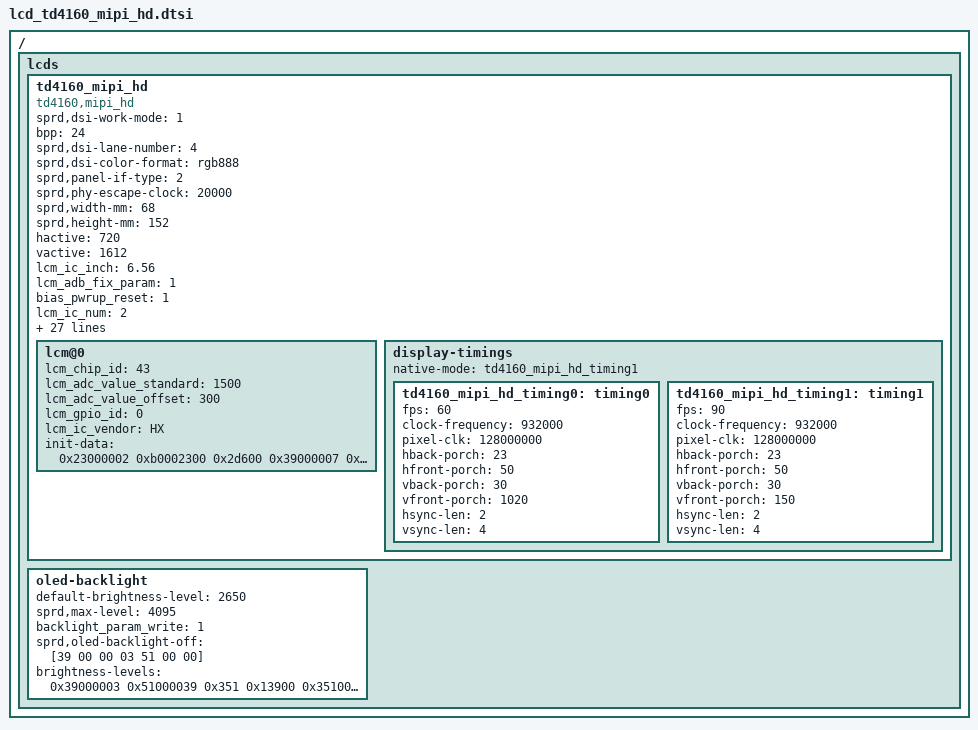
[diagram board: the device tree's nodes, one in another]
/ {
	fragment {
		target-path = "/";
		__overlay__ {
			lcds {
				td4160_mipi_hd: td4160_mipi_hd {
					compatible = "td4160,mipi_hd";
					sprd,dsi-work-mode = <1>; /* video burst mode*/
					bpp = <24>;
					sprd,dsi-lane-number = <4>;
					sprd,dsi-color-format = "rgb888";
					sprd,panel-if-type = <2>;
					sprd,phy-escape-clock = <20000>;
					sprd,width-mm = <68>;
					sprd,height-mm = <152>;
					hactive = <720>;
					vactive = <1612>;
					lcm_ic_inch = "6.56";
					lcm_adb_fix_param = <1>;
					bias_pwrup_reset = <1>;
					lcm_ic_num = <2>;
					lcm_compatible_mode = <1>;
					lcm_adc_channel = <2>;
					tp_touchscreen_rst = <145>;
					tp_touchscreen_irq = <144>;
					tp_touchscreen_cs = <94>;

					sprd,dynamic-framerate-mode;
					sprd,esd-check-enable = <1>;
					sprd,esd-check-mode = <1>;
					sprd,esd-check-period = <2000>;
					sprd,esd-check-register = <10>;
					sprd,esd-check-value = <156>;
					lcm_ic_name = "TD4160";
					lcm_moden_num = <1>;
					lcm_chipid_register = <59>;
					sprd,lcd-id-tokernel = <0x41601>;
					lcm_is_init = <1>;
					power-on-sequence-uboot = <50 1 5 50 0 10 50 1 50>;
					power-on-sequence-kernel = <50 1 5 50 0 10 50 1 50>;
					power-off-sequence = <50 0 1>;
					sprd,oled-backlight-close = [39 00 00 03 51 00 00 23 78 00 02 53 00 13 14 00 01 28];
					sprd,cabc-open = [23 00 00 02 55 01];
					sprd,cabc-close = [23 00 00 02 55 00];
					sleep-in = [13 14 00 01 28 13 78 00 01 10];
					sleep-out = [13 78 00 01 11 13 14 00 01 29];

					lcm@0 {
						lcm_chip_id = <43>;
						lcm_adc_value_standard = <1500>;
						lcm_adc_value_offset = <300>;
						lcm_gpio_id = <0>;
						lcm_ic_vendor = "HX";
						init-data = <0x23000002 0xb0002300 0x2d600 0x39000007 0xb6306a00 0x86c30339 0x5b7 0x31000000 0x39000007 0xb8007864 0x1064b439 0x7b9 0x786410 0x64b43900 0x7ba00 0x78641064 0xb4390000 0x4bb00b4 0xa0390000 0x4bc00b4 0xa0390000 0x4bd00b4 0xa0390000 0xebe070d 0x00 0x00 0x39 0x19c0 0x602206 0x4c001806 0x94007000 0x00 0x00 0x00 0x39000028 0xc1301150 0xfa010000 0x10000000 0x400f00 0x00 0x00 0x00 0x00 0x00 0x00 0x390000f5 0xc203f04c 0x12051008 0x00 0x1010110 0xa000000 0x00 0x00 0x00 0x00 0x00 0x04 0xb03b0c0c 0x5004100 0x46690300 0x64000000 0x1100 0x00 0x00 0x04 0x90360a0a 0x5000166 0xa6730000 0x00 0x1100 0x00 0x00 0x00 0x00 0x00 0x00 0x00 0x1100 0x00 0x00 0x00 0x00 0x00 0x00 0x00 0x1100 0x00 0x00 0x00 0x00 0x00 0x00 0x00 0x00 0x00 0x1000 0x00 0x00 0x00 0x200 0x00 0x00 0x20000 0x00 0x00 0x00 0x00 0x390000 0x6ac30000 0x5dc300c0 0xc3c0c0c 0x20000000 0x00 0x00 0x20000000 0x00 0x00 0x20000000 0x00 0x00 0x20000000 0x80000 0x00 0x00 0x00 0x00 0x00 0x00 0x00 0x00 0x00 0x00 0x00 0x00 0x39 0x55c4 0x707 0x2b272923 0x255d6113 0x1517191b 0x1d030000 0x00 0x00 0x41e1c1a 0x18161461 0x5d26242a 0x282c0707 0x00 0x00 0x00 0x00 0x00 0x00 0x00 0x555555 0x55555555 0x55555555 0x39000006 0xc5080000 0x3900 0x4dc600 0x01 0x22042201 0x5d0000 0x1005d 0x10501 0xb0135ff 0x8f061501 0xc00b0000 0x00 0x00 0x00 0x00 0x00 0x20200000 0xc01100 0x1010 0x01 0x500033 0x3000039 0x1fcb 0x2d00180 0x00 0x00 0x00 0x00 0x4070 0x00 0xff3900 0x19ce5d 0x40434955 0x62718294 0xa8b9cbdb 0xe9f5fcff 0x4000202 0x48c23 0x2cf 0x390000 0x15d0c14a 0x81660990 0xccf2ff 0x1146067e 0x908cc1b 0xf0063900 0x26d1d4 0xd41b3333 0x1707bb33 0x33333300 0x3b77073b 0x30067233 0x1300d70c 0x33020018 0x70187711 0x11112020 0x39000004 0xd2110000 0x3900009a 0xd3000000 0x00 0xfff7 0xfffff7ff 0xfff7ffff 0xf7fffff7 0xfffff7ff 0xfff7ffff 0xf7fffff7 0xfffff7ff 0xfff7ffff 0xf7fffff7 0xfffff7ff 0xfff7ffff 0xf7fffff7 0xfffff7ff 0xfff7ffff 0xf7fffff7 0xfffff7ff 0xfff7ffff 0xf7fffff7 0xfffff7ff 0xfff7ffff 0xf7fffff7 0xfffff7ff 0xfff7ffff 0xf7fffff7 0xfffff7ff 0xfff7ffff 0xf7fffff7 0xfffff7ff 0xfff7ffff 0xf7fffff7 0xfffff7ff 0xfff7ffff 0xf7fffff7 0xfffff7ff 0xfff7ffff 0xf7ff3900 0x18d400 0x00 0x00 0x20000000 0x200000 0x00 0x3900 0x2fd729 0x121200 0x60001800 0x60001803 0x83808585 0x85878445 0x86878088 0x86898383 0x8784888a 0xc0b0a0a 0xa070706 0x600080a 0xa390000 0x17d84099 0x26ed166c 0x166c166c 0x140014 0x14010c 0x100 0x39000029 0xd9000259 0x11b00 0x00 0x00 0xc0000000 0x00 0x00 0x00 0x00 0x00 0x390000 0x5dd3006 0x23653900 0xfde00 0xfff 0x00 0x10000000 0x390000 0x9e60000 0x00 0x3900 0x24ea02 0xe0e0680 0x7407400 0x333 0x70a005e 0x5e005e 0x1280128 0x5e005e 0x5e000c 0x2003900 0x9eb07 0x40740e11 0x1080039 0x18ec 0x5f00170 0x6b074074 0x02 0x2a000000 0x00 0x39 0x22ed 0x1020000 0x100 0x6886fc00 0x00 0x00 0x2b0 0x00 0xc010 0x390000 0x7aee0500 0x5500c05f 0xc05f00 0x30000 0x300c05f 0x00 0xc05f00 0x00 0x30000 0x00 0x3000000 0x03 0xc05f00 0x00 0x30000 0x00 0x3000000 0x03 0x00 0x300 0x30000 0x3000003 0x300 0x30000 0x3000000 0x00 0x00 0x00 0x00 0x00 0x239 0x4f0 0xc1018123 0x235 0x230000 0x2b00339 0x351 0x2300 0x2532c 0x23000002 0x55031350 0x11113 0xa000129>;
					};

					display-timings {
						native-mode = <&td4160_mipi_hd_timing1>;

						td4160_mipi_hd_timing0: timing0 {
							fps = <60>;
							clock-frequency = <932000>;
							pixel-clk = <128000000>;
							hback-porch = <23>;
							hfront-porch = <50>;
							vback-porch = <30>;
							vfront-porch = <1020>;
							hsync-len = <2>;
							vsync-len = <4>;
						};

						td4160_mipi_hd_timing1: timing1 {
							fps = <90>;
							clock-frequency = <932000>;
							pixel-clk = <128000000>;
							hback-porch = <23>;
							hfront-porch = <50>;
							vback-porch = <30>;
							vfront-porch = <150>;
							hsync-len = <2>;
							vsync-len = <4>;
						};
					};
				};

				oled-backlight {
					default-brightness-level = <2650>;
					sprd,max-level = <4095>;
					backlight_param_write = <1>;
					sprd,oled-backlight-off = [39 00 00 03 51 00 00];
					brightness-levels = <0x39000003 0x51000039 0x351 0x13900 0x35100 0x2390000 0x3510003 0x39000003 0x51000439 0x351 0x53900 0x35100 0x6390000 0x3510007 0x39000003 0x51000839 0x351 0x93900 0x35100 0xa390000 0x351000b 0x39000003 0x51000c39 0x351 0xd3900 0x35100 0xe390000 0x351000f 0x39000003 0x51001039 0x351 0x113900 0x35100 0x12390000 0x3510013 0x39000003 0x51001439 0x351 0x153900 0x35100 0x16390000 0x3510017 0x39000003 0x51001839 0x351 0x193900 0x35100 0x1a390000 0x351001b 0x39000003 0x51001c39 0x351 0x1d3900 0x35100 0x1e390000 0x351001f 0x39000003 0x51002039 0x351 0x213900 0x35100 0x22390000 0x3510023 0x39000003 0x51002439 0x351 0x253900 0x35100 0x26390000 0x3510027 0x39000003 0x51002839 0x351 0x293900 0x35100 0x2a390000 0x351002b 0x39000003 0x51002c39 0x351 0x2d3900 0x35100 0x2e390000 0x351002f 0x39000003 0x51003039 0x351 0x313900 0x35100 0x32390000 0x3510033 0x39000003 0x51003439 0x351 0x353900 0x35100 0x36390000 0x3510037 0x39000003 0x51003839 0x351 0x393900 0x35100 0x3a390000 0x351003b 0x39000003 0x51003c39 0x351 0x3d3900 0x35100 0x3e390000 0x351003f 0x39000003 0x51004039 0x351 0x413900 0x35100 0x42390000 0x3510043 0x39000003 0x51004439 0x351 0x453900 0x35100 0x46390000 0x3510047 0x39000003 0x51004839 0x351 0x493900 0x35100 0x4a390000 0x351004b 0x39000003 0x51004c39 0x351 0x4d3900 0x35100 0x4e390000 0x351004f 0x39000003 0x51005039 0x351 0x513900 0x35100 0x52390000 0x3510053 0x39000003 0x51005439 0x351 0x553900 0x35100 0x56390000 0x3510057 0x39000003 0x51005839 0x351 0x593900 0x35100 0x5a390000 0x351005b 0x39000003 0x51005c39 0x351 0x5d3900 0x35100 0x5e390000 0x351005f 0x39000003 0x51006039 0x351 0x613900 0x35100 0x62390000 0x3510063 0x39000003 0x51006439 0x351 0x653900 0x35100 0x66390000 0x3510067 0x39000003 0x51006839 0x351 0x693900 0x35100 0x6a390000 0x351006b 0x39000003 0x51006c39 0x351 0x6d3900 0x35100 0x6e390000 0x351006f 0x39000003 0x51007039 0x351 0x713900 0x35100 0x72390000 0x3510073 0x39000003 0x51007439 0x351 0x753900 0x35100 0x76390000 0x3510077 0x39000003 0x51007839 0x351 0x793900 0x35100 0x7a390000 0x351007b 0x39000003 0x51007c39 0x351 0x7d3900 0x35100 0x7e390000 0x351007f 0x39000003 0x51008039 0x351 0x813900 0x35100 0x82390000 0x3510083 0x39000003 0x51008439 0x351 0x853900 0x35100 0x86390000 0x3510087 0x39000003 0x51008839 0x351 0x893900 0x35100 0x8a390000 0x351008b 0x39000003 0x51008c39 0x351 0x8d3900 0x35100 0x8e390000 0x351008f 0x39000003 0x51009039 0x351 0x913900 0x35100 0x92390000 0x3510093 0x39000003 0x51009439 0x351 0x953900 0x35100 0x96390000 0x3510097 0x39000003 0x51009839 0x351 0x993900 0x35100 0x9a390000 0x351009b 0x39000003 0x51009c39 0x351 0x9d3900 0x35100 0x9e390000 0x351009f 0x39000003 0x5100a039 0x351 0xa13900 0x35100 0xa2390000 0x35100a3 0x39000003 0x5100a439 0x351 0xa53900 0x35100 0xa6390000 0x35100a7 0x39000003 0x5100a839 0x351 0xa93900 0x35100 0xaa390000 0x35100ab 0x39000003 0x5100ac39 0x351 0xad3900 0x35100 0xae390000 0x35100af 0x39000003 0x5100b039 0x351 0xb13900 0x35100 0xb2390000 0x35100b3 0x39000003 0x5100b439 0x351 0xb53900 0x35100 0xb6390000 0x35100b7 0x39000003 0x5100b839 0x351 0xb93900 0x35100 0xba390000 0x35100bb 0x39000003 0x5100bc39 0x351 0xbd3900 0x35100 0xbe390000 0x35100bf 0x39000003 0x5100c039 0x351 0xc13900 0x35100 0xc2390000 0x35100c3 0x39000003 0x5100c439 0x351 0xc53900 0x35100 0xc6390000 0x35100c7 0x39000003 0x5100c839 0x351 0xc93900 0x35100 0xca390000 0x35100cb 0x39000003 0x5100cc39 0x351 0xcd3900 0x35100 0xce390000 0x35100cf 0x39000003 0x5100d039 0x351 0xd13900 0x35100 0xd2390000 0x35100d3 0x39000003 0x5100d439 0x351 0xd53900 0x35100 0xd6390000 0x35100d7 0x39000003 0x5100d839 0x351 0xd93900 0x35100 0xda390000 0x35100db 0x39000003 0x5100dc39 0x351 0xdd3900 0x35100 0xde390000 0x35100df 0x39000003 0x5100e039 0x351 0xe13900 0x35100 0xe2390000 0x35100e3 0x39000003 0x5100e439 0x351 0xe53900 0x35100 0xe6390000 0x35100e7 0x39000003 0x5100e839 0x351 0xe93900 0x35100 0xea390000 0x35100eb 0x39000003 0x5100ec39 0x351 0xed3900 0x35100 0xee390000 0x35100ef 0x39000003 0x5100f039 0x351 0xf13900 0x35100 0xf2390000 0x35100f3 0x39000003 0x5100f439 0x351 0xf53900 0x35100 0xf6390000 0x35100f7 0x39000003 0x5100f839 0x351 0xf93900 0x35100 0xfa390000 0x35100fb 0x39000003 0x5100fc39 0x351 0xfd3900 0x35100 0xfe390000 0x35100ff 0x39000003 0x51010039 0x351 0x1013900 0x35101 0x2390000 0x3510103 0x39000003 0x51010439 0x351 0x1053900 0x35101 0x6390000 0x3510107 0x39000003 0x51010839 0x351 0x1093900 0x35101 0xa390000 0x351010b 0x39000003 0x51010c39 0x351 0x10d3900 0x35101 0xe390000 0x351010f 0x39000003 0x51011039 0x351 0x1113900 0x35101 0x12390000 0x3510113 0x39000003 0x51011439 0x351 0x1153900 0x35101 0x16390000 0x3510117 0x39000003 0x51011839 0x351 0x1193900 0x35101 0x1a390000 0x351011b 0x39000003 0x51011c39 0x351 0x11d3900 0x35101 0x1e390000 0x351011f 0x39000003 0x51012039 0x351 0x1213900 0x35101 0x22390000 0x3510123 0x39000003 0x51012439 0x351 0x1253900 0x35101 0x26390000 0x3510127 0x39000003 0x51012839 0x351 0x1293900 0x35101 0x2a390000 0x351012b 0x39000003 0x51012c39 0x351 0x12d3900 0x35101 0x2e390000 0x351012f 0x39000003 0x51013039 0x351 0x1313900 0x35101 0x32390000 0x3510133 0x39000003 0x51013439 0x351 0x1353900 0x35101 0x36390000 0x3510137 0x39000003 0x51013839 0x351 0x1393900 0x35101 0x3a390000 0x351013b 0x39000003 0x51013c39 0x351 0x13d3900 0x35101 0x3e390000 0x351013f 0x39000003 0x51014039 0x351 0x1413900 0x35101 0x42390000 0x3510143 0x39000003 0x51014439 0x351 0x1453900 0x35101 0x46390000 0x3510147 0x39000003 0x51014839 0x351 0x1493900 0x35101 0x4a390000 0x351014b 0x39000003 0x51014c39 0x351 0x14d3900 0x35101 0x4e390000 0x351014f 0x39000003 0x51015039 0x351 0x1513900 0x35101 0x52390000 0x3510153 0x39000003 0x51015439 0x351 0x1553900 0x35101 0x56390000 0x3510157 0x39000003 0x51015839 0x351 0x1593900 0x35101 0x5a390000 0x351015b 0x39000003 0x51015c39 0x351 0x15d3900 0x35101 0x5e390000 0x351015f 0x39000003 0x51016039 0x351 0x1613900 0x35101 0x62390000 0x3510163 0x39000003 0x51016439 0x351 0x1653900 0x35101 0x66390000 0x3510167 0x39000003 0x51016839 0x351 0x1693900 0x35101 0x6a390000 0x351016b 0x39000003 0x51016c39 0x351 0x16d3900 0x35101 0x6e390000 0x351016f 0x39000003 0x51017039 0x351 0x1713900 0x35101 0x72390000 0x3510173 0x39000003 0x51017439 0x351 0x1753900 0x35101 0x76390000 0x3510177 0x39000003 0x51017839 0x351 0x1793900 0x35101 0x7a390000 0x351017b 0x39000003 0x51017c39 0x351 0x17d3900 0x35101 0x7e390000 0x351017f 0x39000003 0x51018039 0x351 0x1813900 0x35101 0x82390000 0x3510183 0x39000003 0x51018439 0x351 0x1853900 0x35101 0x86390000 0x3510187 0x39000003 0x51018839 0x351 0x1893900 0x35101 0x8a390000 0x351018b 0x39000003 0x51018c39 0x351 0x18d3900 0x35101 0x8e390000 0x351018f 0x39000003 0x51019039 0x351 0x1913900 0x35101 0x92390000 0x3510193 0x39000003 0x51019439 0x351 0x1953900 0x35101 0x96390000 0x3510197 0x39000003 0x51019839 0x351 0x1993900 0x35101 0x9a390000 0x351019b 0x39000003 0x51019c39 0x351 0x19d3900 0x35101 0x9e390000 0x351019f 0x39000003 0x5101a039 0x351 0x1a13900 0x35101 0xa2390000 0x35101a3 0x39000003 0x5101a439 0x351 0x1a53900 0x35101 0xa6390000 0x35101a7 0x39000003 0x5101a839 0x351 0x1a93900 0x35101 0xaa390000 0x35101ab 0x39000003 0x5101ac39 0x351 0x1ad3900 0x35101 0xae390000 0x35101af 0x39000003 0x5101b039 0x351 0x1b13900 0x35101 0xb2390000 0x35101b3 0x39000003 0x5101b439 0x351 0x1b53900 0x35101 0xb6390000 0x35101b7 0x39000003 0x5101b839 0x351 0x1b93900 0x35101 0xba390000 0x35101bb 0x39000003 0x5101bc39 0x351 0x1bd3900 0x35101 0xbe390000 0x35101bf 0x39000003 0x5101c039 0x351 0x1c13900 0x35101 0xc2390000 0x35101c3 0x39000003 0x5101c439 0x351 0x1c53900 0x35101 0xc6390000 0x35101c7 0x39000003 0x5101c839 0x351 0x1c93900 0x35101 0xca390000 0x35101cb 0x39000003 0x5101cc39 0x351 0x1cd3900 0x35101 0xce390000 0x35101cf 0x39000003 0x5101d039 0x351 0x1d13900 0x35101 0xd2390000 0x35101d3 0x39000003 0x5101d439 0x351 0x1d53900 0x35101 0xd6390000 0x35101d7 0x39000003 0x5101d839 0x351 0x1d93900 0x35101 0xda390000 0x35101db 0x39000003 0x5101dc39 0x351 0x1dd3900 0x35101 0xde390000 0x35101df 0x39000003 0x5101e039 0x351 0x1e13900 0x35101 0xe2390000 0x35101e3 0x39000003 0x5101e439 0x351 0x1e53900 0x35101 0xe6390000 0x35101e7 0x39000003 0x5101e839 0x351 0x1e93900 0x35101 0xea390000 0x35101eb 0x39000003 0x5101ec39 0x351 0x1ed3900 0x35101 0xee390000 0x35101ef 0x39000003 0x5101f039 0x351 0x1f13900 0x35101 0xf2390000 0x35101f3 0x39000003 0x5101f439 0x351 0x1f53900 0x35101 0xf6390000 0x35101f7 0x39000003 0x5101f839 0x351 0x1f93900 0x35101 0xfa390000 0x35101fb 0x39000003 0x5101fc39 0x351 0x1fd3900 0x35101 0xfe390000 0x35101ff 0x39000003 0x51020039 0x351 0x2013900 0x35102 0x2390000 0x3510203 0x39000003 0x51020439 0x351 0x2053900 0x35102 0x6390000 0x3510207 0x39000003 0x51020839 0x351 0x2093900 0x35102 0xa390000 0x351020b 0x39000003 0x51020c39 0x351 0x20d3900 0x35102 0xe390000 0x351020f 0x39000003 0x51021039 0x351 0x2113900 0x35102 0x12390000 0x3510213 0x39000003 0x51021439 0x351 0x2153900 0x35102 0x16390000 0x3510217 0x39000003 0x51021839 0x351 0x2193900 0x35102 0x1a390000 0x351021b 0x39000003 0x51021c39 0x351 0x21d3900 0x35102 0x1e390000 0x351021f 0x39000003 0x51022039 0x351 0x2213900 0x35102 0x22390000 0x3510223 0x39000003 0x51022439 0x351 0x2253900 0x35102 0x26390000 0x3510227 0x39000003 0x51022839 0x351 0x2293900 0x35102 0x2a390000 0x351022b 0x39000003 0x51022c39 0x351 0x22d3900 0x35102 0x2e390000 0x351022f 0x39000003 0x51023039 0x351 0x2313900 0x35102 0x32390000 0x3510233 0x39000003 0x51023439 0x351 0x2353900 0x35102 0x36390000 0x3510237 0x39000003 0x51023839 0x351 0x2393900 0x35102 0x3a390000 0x351023b 0x39000003 0x51023c39 0x351 0x23d3900 0x35102 0x3e390000 0x351023f 0x39000003 0x51024039 0x351 0x2413900 0x35102 0x42390000 0x3510243 0x39000003 0x51024439 0x351 0x2453900 0x35102 0x46390000 0x3510247 0x39000003 0x51024839 0x351 0x2493900 0x35102 0x4a390000 0x351024b 0x39000003 0x51024c39 0x351 0x24d3900 0x35102 0x4e390000 0x351024f 0x39000003 0x51025039 0x351 0x2513900 0x35102 0x52390000 0x3510253 0x39000003 0x51025439 0x351 0x2553900 0x35102 0x56390000 0x3510257 0x39000003 0x51025839 0x351 0x2593900 0x35102 0x5a390000 0x351025b 0x39000003 0x51025c39 0x351 0x25d3900 0x35102 0x5e390000 0x351025f 0x39000003 0x51026039 0x351 0x2613900 0x35102 0x62390000 0x3510263 0x39000003 0x51026439 0x351 0x2653900 0x35102 0x66390000 0x3510267 0x39000003 0x51026839 0x351 0x2693900 0x35102 0x6a390000 0x351026b 0x39000003 0x51026c39 0x351 0x26d3900 0x35102 0x6e390000 0x351026f 0x39000003 0x51027039 0x351 0x2713900 0x35102 0x72390000 0x3510273 0x39000003 0x51027439 0x351 0x2753900 0x35102 0x76390000 0x3510277 0x39000003 0x51027839 0x351 0x2793900 0x35102 0x7a390000 0x351027b 0x39000003 0x51027c39 0x351 0x27d3900 0x35102 0x7e390000 0x351027f 0x39000003 0x51028039 0x351 0x2813900 0x35102 0x82390000 0x3510283 0x39000003 0x51028439 0x351 0x2853900 0x35102 0x86390000 0x3510287 0x39000003 0x51028839 0x351 0x2893900 0x35102 0x8a390000 0x351028b 0x39000003 0x51028c39 0x351 0x28d3900 0x35102 0x8e390000 0x351028f 0x39000003 0x51029039 0x351 0x2913900 0x35102 0x92390000 0x3510293 0x39000003 0x51029439 0x351 0x2953900 0x35102 0x96390000 0x3510297 0x39000003 0x51029839 0x351 0x2993900 0x35102 0x9a390000 0x351029b 0x39000003 0x51029c39 0x351 0x29d3900 0x35102 0x9e390000 0x351029f 0x39000003 0x5102a039 0x351 0x2a13900 0x35102 0xa2390000 0x35102a3 0x39000003 0x5102a439 0x351 0x2a53900 0x35102 0xa6390000 0x35102a7 0x39000003 0x5102a839 0x351 0x2a93900 0x35102 0xaa390000 0x35102ab 0x39000003 0x5102ac39 0x351 0x2ad3900 0x35102 0xae390000 0x35102af 0x39000003 0x5102b039 0x351 0x2b13900 0x35102 0xb2390000 0x35102b3 0x39000003 0x5102b439 0x351 0x2b53900 0x35102 0xb6390000 0x35102b7 0x39000003 0x5102b839 0x351 0x2b93900 0x35102 0xba390000 0x35102bb 0x39000003 0x5102bc39 0x351 0x2bd3900 0x35102 0xbe390000 0x35102bf 0x39000003 0x5102c039 0x351 0x2c13900 0x35102 0xc2390000 0x35102c3 0x39000003 0x5102c439 0x351 0x2c53900 0x35102 0xc6390000 0x35102c7 0x39000003 0x5102c839 0x351 0x2c93900 0x35102 0xca390000 0x35102cb 0x39000003 0x5102cc39 0x351 0x2cd3900 0x35102 0xce390000 0x35102cf 0x39000003 0x5102d039 0x351 0x2d13900 0x35102 0xd2390000 0x35102d3 0x39000003 0x5102d439 0x351 0x2d53900 0x35102 0xd6390000 0x35102d7 0x39000003 0x5102d839 0x351 0x2d93900 0x35102 0xda390000 0x35102db 0x39000003 0x5102dc39 0x351 0x2dd3900 0x35102 0xde390000 0x35102df 0x39000003 0x5102e039 0x351 0x2e13900 0x35102 0xe2390000 0x35102e3 0x39000003 0x5102e439 0x351 0x2e53900 0x35102 0xe6390000 0x35102e7 0x39000003 0x5102e839 0x351 0x2e93900 0x35102 0xea390000 0x35102eb 0x39000003 0x5102ec39 0x351 0x2ed3900 0x35102 0xee390000 0x35102ef 0x39000003 0x5102f039 0x351 0x2f13900 0x35102 0xf2390000 0x35102f3 0x39000003 0x5102f439 0x351 0x2f53900 0x35102 0xf6390000 0x35102f7 0x39000003 0x5102f839 0x351 0x2f93900 0x35102 0xfa390000 0x35102fb 0x39000003 0x5102fc39 0x351 0x2fd3900 0x35102 0xfe390000 0x35102ff 0x39000003 0x51030039 0x351 0x3013900 0x35103 0x2390000 0x3510303 0x39000003 0x51030439 0x351 0x3053900 0x35103 0x6390000 0x3510307 0x39000003 0x51030839 0x351 0x3093900 0x35103 0xa390000 0x351030b 0x39000003 0x51030c39 0x351 0x30d3900 0x35103 0xe390000 0x351030f 0x39000003 0x51031039 0x351 0x3113900 0x35103 0x12390000 0x3510313 0x39000003 0x51031439 0x351 0x3153900 0x35103 0x16390000 0x3510317 0x39000003 0x51031839 0x351 0x3193900 0x35103 0x1a390000 0x351031b 0x39000003 0x51031c39 0x351 0x31d3900 0x35103 0x1e390000 0x351031f 0x39000003 0x51032039 0x351 0x3213900 0x35103 0x22390000 0x3510323 0x39000003 0x51032439 0x351 0x3253900 0x35103 0x26390000 0x3510327 0x39000003 0x51032839 0x351 0x3293900 0x35103 0x2a390000 0x351032b 0x39000003 0x51032c39 0x351 0x32d3900 0x35103 0x2e390000 0x351032f 0x39000003 0x51033039 0x351 0x3313900 0x35103 0x32390000 0x3510333 0x39000003 0x51033439 0x351 0x3353900 0x35103 0x36390000 0x3510337 0x39000003 0x51033839 0x351 0x3393900 0x35103 0x3a390000 0x351033b 0x39000003 0x51033c39 0x351 0x33d3900 0x35103 0x3e390000 0x351033f 0x39000003 0x51034039 0x351 0x3413900 0x35103 0x42390000 0x3510343 0x39000003 0x51034439 0x351 0x3453900 0x35103 0x46390000 0x3510347 0x39000003 0x51034839 0x351 0x3493900 0x35103 0x4a390000 0x351034b 0x39000003 0x51034c39 0x351 0x34d3900 0x35103 0x4e390000 0x351034f 0x39000003 0x51035039 0x351 0x3513900 0x35103 0x52390000 0x3510353 0x39000003 0x51035439 0x351 0x3553900 0x35103 0x56390000 0x3510357 0x39000003 0x51035839 0x351 0x3593900 0x35103 0x5a390000 0x351035b 0x39000003 0x51035c39 0x351 0x35d3900 0x35103 0x5e390000 0x351035f 0x39000003 0x51036039 0x351 0x3613900 0x35103 0x62390000 0x3510363 0x39000003 0x51036439 0x351 0x3653900 0x35103 0x66390000 0x3510367 0x39000003 0x51036839 0x351 0x3693900 0x35103 0x6a390000 0x351036b 0x39000003 0x51036c39 0x351 0x36d3900 0x35103 0x6e390000 0x351036f 0x39000003 0x51037039 0x351 0x3713900 0x35103 0x72390000 0x3510373 0x39000003 0x51037439 0x351 0x3753900 0x35103 0x76390000 0x3510377 0x39000003 0x51037839 0x351 0x3793900 0x35103 0x7a390000 0x351037b 0x39000003 0x51037c39 0x351 0x37d3900 0x35103 0x7e390000 0x351037f 0x39000003 0x51038039 0x351 0x3813900 0x35103 0x82390000 0x3510383 0x39000003 0x51038439 0x351 0x3853900 0x35103 0x86390000 0x3510387 0x39000003 0x51038839 0x351 0x3893900 0x35103 0x8a390000 0x351038b 0x39000003 0x51038c39 0x351 0x38d3900 0x35103 0x8e390000 0x351038f 0x39000003 0x51039039 0x351 0x3913900 0x35103 0x92390000 0x3510393 0x39000003 0x51039439 0x351 0x3953900 0x35103 0x96390000 0x3510397 0x39000003 0x51039839 0x351 0x3993900 0x35103 0x9a390000 0x351039b 0x39000003 0x51039c39 0x351 0x39d3900 0x35103 0x9e390000 0x351039f 0x39000003 0x5103a039 0x351 0x3a13900 0x35103 0xa2390000 0x35103a3 0x39000003 0x5103a439 0x351 0x3a53900 0x35103 0xa6390000 0x35103a7 0x39000003 0x5103a839 0x351 0x3a93900 0x35103 0xaa390000 0x35103ab 0x39000003 0x5103ac39 0x351 0x3ad3900 0x35103 0xae390000 0x35103af 0x39000003 0x5103b039 0x351 0x3b13900 0x35103 0xb2390000 0x35103b3 0x39000003 0x5103b439 0x351 0x3b53900 0x35103 0xb6390000 0x35103b7 0x39000003 0x5103b839 0x351 0x3b93900 0x35103 0xba390000 0x35103bb 0x39000003 0x5103bc39 0x351 0x3bd3900 0x35103 0xbe390000 0x35103bf 0x39000003 0x5103c039 0x351 0x3c13900 0x35103 0xc2390000 0x35103c3 0x39000003 0x5103c439 0x351 0x3c53900 0x35103 0xc6390000 0x35103c7 0x39000003 0x5103c839 0x351 0x3c93900 0x35103 0xca390000 0x35103cb 0x39000003 0x5103cc39 0x351 0x3cd3900 0x35103 0xce390000 0x35103cf 0x39000003 0x5103d039 0x351 0x3d13900 0x35103 0xd2390000 0x35103d3 0x39000003 0x5103d439 0x351 0x3d53900 0x35103 0xd6390000 0x35103d7 0x39000003 0x5103d839 0x351 0x3d93900 0x35103 0xda390000 0x35103db 0x39000003 0x5103dc39 0x351 0x3dd3900 0x35103 0xde390000 0x35103df 0x39000003 0x5103e039 0x351 0x3e13900 0x35103 0xe2390000 0x35103e3 0x39000003 0x5103e439 0x351 0x3e53900 0x35103 0xe6390000 0x35103e7 0x39000003 0x5103e839 0x351 0x3e93900 0x35103 0xea390000 0x35103eb 0x39000003 0x5103ec39 0x351 0x3ed3900 0x35103 0xee390000 0x35103ef 0x39000003 0x5103f039 0x351 0x3f13900 0x35103 0xf2390000 0x35103f3 0x39000003 0x5103f439 0x351 0x3f53900 0x35103 0xf6390000 0x35103f7 0x39000003 0x5103f839 0x351 0x3f93900 0x35103 0xfa390000 0x35103fb 0x39000003 0x5103fc39 0x351 0x3fd3900 0x35103 0xfe390000 0x35103ff 0x39000003 0x51040039 0x351 0x4013900 0x35104 0x2390000 0x3510403 0x39000003 0x51040439 0x351 0x4053900 0x35104 0x6390000 0x3510407 0x39000003 0x51040839 0x351 0x4093900 0x35104 0xa390000 0x351040b 0x39000003 0x51040c39 0x351 0x40d3900 0x35104 0xe390000 0x351040f 0x39000003 0x51041039 0x351 0x4113900 0x35104 0x12390000 0x3510413 0x39000003 0x51041439 0x351 0x4153900 0x35104 0x16390000 0x3510417 0x39000003 0x51041839 0x351 0x4193900 0x35104 0x1a390000 0x351041b 0x39000003 0x51041c39 0x351 0x41d3900 0x35104 0x1e390000 0x351041f 0x39000003 0x51042039 0x351 0x4213900 0x35104 0x22390000 0x3510423 0x39000003 0x51042439 0x351 0x4253900 0x35104 0x26390000 0x3510427 0x39000003 0x51042839 0x351 0x4293900 0x35104 0x2a390000 0x351042b 0x39000003 0x51042c39 0x351 0x42d3900 0x35104 0x2e390000 0x351042f 0x39000003 0x51043039 0x351 0x4313900 0x35104 0x32390000 0x3510433 0x39000003 0x51043439 0x351 0x4353900 0x35104 0x36390000 0x3510437 0x39000003 0x51043839 0x351 0x4393900 0x35104 0x3a390000 0x351043b 0x39000003 0x51043c39 0x351 0x43d3900 0x35104 0x3e390000 0x351043f 0x39000003 0x51044039 0x351 0x4413900 0x35104 0x42390000 0x3510443 0x39000003 0x51044439 0x351 0x4453900 0x35104 0x46390000 0x3510447 0x39000003 0x51044839 0x351 0x4493900 0x35104 0x4a390000 0x351044b 0x39000003 0x51044c39 0x351 0x44d3900 0x35104 0x4e390000 0x351044f 0x39000003 0x51045039 0x351 0x4513900 0x35104 0x52390000 0x3510453 0x39000003 0x51045439 0x351 0x4553900 0x35104 0x56390000 0x3510457 0x39000003 0x51045839 0x351 0x4593900 0x35104 0x5a390000 0x351045b 0x39000003 0x51045c39 0x351 0x45d3900 0x35104 0x5e390000 0x351045f 0x39000003 0x51046039 0x351 0x4613900 0x35104 0x62390000 0x3510463 0x39000003 0x51046439 0x351 0x4653900 0x35104 0x66390000 0x3510467 0x39000003 0x51046839 0x351 0x4693900 0x35104 0x6a390000 0x351046b 0x39000003 0x51046c39 0x351 0x46d3900 0x35104 0x6e390000 0x351046f 0x39000003 0x51047039 0x351 0x4713900 0x35104 0x72390000 0x3510473 0x39000003 0x51047439 0x351 0x4753900 0x35104 0x76390000 0x3510477 0x39000003 0x51047839 0x351 0x4793900 0x35104 0x7a390000 0x351047b 0x39000003 0x51047c39 0x351 0x47d3900 0x35104 0x7e390000 0x351047f 0x39000003 0x51048039 0x351 0x4813900 0x35104 0x82390000 0x3510483 0x39000003 0x51048439 0x351 0x4853900 0x35104 0x86390000 0x3510487 0x39000003 0x51048839 0x351 0x4893900 0x35104 0x8a390000 0x351048b 0x39000003 0x51048c39 0x351 0x48d3900 0x35104 0x8e390000 0x351048f 0x39000003 0x51049039 0x351 0x4913900 0x35104 0x92390000 0x3510493 0x39000003 0x51049439 0x351 0x4953900 0x35104 0x96390000 0x3510497 0x39000003 0x51049839 0x351 0x4993900 0x35104 0x9a390000 0x351049b 0x39000003 0x51049c39 0x351 0x49d3900 0x35104 0x9e390000 0x351049f 0x39000003 0x5104a039 0x351 0x4a13900 0x35104 0xa2390000 0x35104a3 0x39000003 0x5104a439 0x351 0x4a53900 0x35104 0xa6390000 0x35104a7 0x39000003 0x5104a839 0x351 0x4a93900 0x35104 0xaa390000 0x35104ab 0x39000003 0x5104ac39 0x351 0x4ad3900 0x35104 0xae390000 0x35104af 0x39000003 0x5104b039 0x351 0x4b13900 0x35104 0xb2390000 0x35104b3 0x39000003 0x5104b439 0x351 0x4b53900 0x35104 0xb6390000 0x35104b7 0x39000003 0x5104b839 0x351 0x4b93900 0x35104 0xba390000 0x35104bb 0x39000003 0x5104bc39 0x351 0x4bd3900 0x35104 0xbe390000 0x35104bf 0x39000003 0x5104c039 0x351 0x4c13900 0x35104 0xc2390000 0x35104c3 0x39000003 0x5104c439 0x351 0x4c53900 0x35104 0xc6390000 0x35104c7 0x39000003 0x5104c839 0x351 0x4c93900 0x35104 0xca390000 0x35104cb 0x39000003 0x5104cc39 0x351 0x4cd3900 0x35104 0xce390000 0x35104cf 0x39000003 0x5104d039 0x351 0x4d13900 0x35104 0xd2390000 0x35104d3 0x39000003 0x5104d439 0x351 0x4d53900 0x35104 0xd6390000 0x35104d7 0x39000003 0x5104d839 0x351 0x4d93900 0x35104 0xda390000 0x35104db 0x39000003 0x5104dc39 0x351 0x4dd3900 0x35104 0xde390000 0x35104df 0x39000003 0x5104e039 0x351 0x4e13900 0x35104 0xe2390000 0x35104e3 0x39000003 0x5104e439 0x351 0x4e53900 0x35104 0xe6390000 0x35104e7 0x39000003 0x5104e839 0x351 0x4e93900 0x35104 0xea390000 0x35104eb 0x39000003 0x5104ec39 0x351 0x4ed3900 0x35104 0xee390000 0x35104ef 0x39000003 0x5104f039 0x351 0x4f13900 0x35104 0xf2390000 0x35104f3 0x39000003 0x5104f439 0x351 0x4f53900 0x35104 0xf6390000 0x35104f7 0x39000003 0x5104f839 0x351 0x4f93900 0x35104 0xfa390000 0x35104fb 0x39000003 0x5104fc39 0x351 0x4fd3900 0x35104 0xfe390000 0x35104ff 0x39000003 0x51050039 0x351 0x5013900 0x35105 0x2390000 0x3510503 0x39000003 0x51050439 0x351 0x5053900 0x35105 0x6390000 0x3510507 0x39000003 0x51050839 0x351 0x5093900 0x35105 0xa390000 0x351050b 0x39000003 0x51050c39 0x351 0x50d3900 0x35105 0xe390000 0x351050f 0x39000003 0x51051039 0x351 0x5113900 0x35105 0x12390000 0x3510513 0x39000003 0x51051439 0x351 0x5153900 0x35105 0x16390000 0x3510517 0x39000003 0x51051839 0x351 0x5193900 0x35105 0x1a390000 0x351051b 0x39000003 0x51051c39 0x351 0x51d3900 0x35105 0x1e390000 0x351051f 0x39000003 0x51052039 0x351 0x5213900 0x35105 0x22390000 0x3510523 0x39000003 0x51052439 0x351 0x5253900 0x35105 0x26390000 0x3510527 0x39000003 0x51052839 0x351 0x5293900 0x35105 0x2a390000 0x351052b 0x39000003 0x51052c39 0x351 0x52d3900 0x35105 0x2e390000 0x351052f 0x39000003 0x51053039 0x351 0x5313900 0x35105 0x32390000 0x3510533 0x39000003 0x51053439 0x351 0x5353900 0x35105 0x36390000 0x3510537 0x39000003 0x51053839 0x351 0x5393900 0x35105 0x3a390000 0x351053b 0x39000003 0x51053c39 0x351 0x53d3900 0x35105 0x3e390000 0x351053f 0x39000003 0x51054039 0x351 0x5413900 0x35105 0x42390000 0x3510543 0x39000003 0x51054439 0x351 0x5453900 0x35105 0x46390000 0x3510547 0x39000003 0x51054839 0x351 0x5493900 0x35105 0x4a390000 0x351054b 0x39000003 0x51054c39 0x351 0x54d3900 0x35105 0x4e390000 0x351054f 0x39000003 0x51055039 0x351 0x5513900 0x35105 0x52390000 0x3510553 0x39000003 0x51055439 0x351 0x5553900 0x35105 0x56390000 0x3510557 0x39000003 0x51055839 0x351 0x5593900 0x35105 0x5a390000 0x351055b 0x39000003 0x51055c39 0x351 0x55d3900 0x35105 0x5e390000 0x351055f 0x39000003 0x51056039 0x351 0x5613900 0x35105 0x62390000 0x3510563 0x39000003 0x51056439 0x351 0x5653900 0x35105 0x66390000 0x3510567 0x39000003 0x51056839 0x351 0x5693900 0x35105 0x6a390000 0x351056b 0x39000003 0x51056c39 0x351 0x56d3900 0x35105 0x6e390000 0x351056f 0x39000003 0x51057039 0x351 0x5713900 0x35105 0x72390000 0x3510573 0x39000003 0x51057439 0x351 0x5753900 0x35105 0x76390000 0x3510577 0x39000003 0x51057839 0x351 0x5793900 0x35105 0x7a390000 0x351057b 0x39000003 0x51057c39 0x351 0x57d3900 0x35105 0x7e390000 0x351057f 0x39000003 0x51058039 0x351 0x5813900 0x35105 0x82390000 0x3510583 0x39000003 0x51058439 0x351 0x5853900 0x35105 0x86390000 0x3510587 0x39000003 0x51058839 0x351 0x5893900 0x35105 0x8a390000 0x351058b 0x39000003 0x51058c39 0x351 0x58d3900 0x35105 0x8e390000 0x351058f 0x39000003 0x51059039 0x351 0x5913900 0x35105 0x92390000 0x3510593 0x39000003 0x51059439 0x351 0x5953900 0x35105 0x96390000 0x3510597 0x39000003 0x51059839 0x351 0x5993900 0x35105 0x9a390000 0x351059b 0x39000003 0x51059c39 0x351 0x59d3900 0x35105 0x9e390000 0x351059f 0x39000003 0x5105a039 0x351 0x5a13900 0x35105 0xa2390000 0x35105a3 0x39000003 0x5105a439 0x351 0x5a53900 0x35105 0xa6390000 0x35105a7 0x39000003 0x5105a839 0x351 0x5a93900 0x35105 0xaa390000 0x35105ab 0x39000003 0x5105ac39 0x351 0x5ad3900 0x35105 0xae390000 0x35105af 0x39000003 0x5105b039 0x351 0x5b13900 0x35105 0xb2390000 0x35105b3 0x39000003 0x5105b439 0x351 0x5b53900 0x35105 0xb6390000 0x35105b7 0x39000003 0x5105b839 0x351 0x5b93900 0x35105 0xba390000 0x35105bb 0x39000003 0x5105bc39 0x351 0x5bd3900 0x35105 0xbe390000 0x35105bf 0x39000003 0x5105c039 0x351 0x5c13900 0x35105 0xc2390000 0x35105c3 0x39000003 0x5105c439 0x351 0x5c53900 0x35105 0xc6390000 0x35105c7 0x39000003 0x5105c839 0x351 0x5c93900 0x35105 0xca390000 0x35105cb 0x39000003 0x5105cc39 0x351 0x5cd3900 0x35105 0xce390000 0x35105cf 0x39000003 0x5105d039 0x351 0x5d13900 0x35105 0xd2390000 0x35105d3 0x39000003 0x5105d439 0x351 0x5d53900 0x35105 0xd6390000 0x35105d7 0x39000003 0x5105d839 0x351 0x5d93900 0x35105 0xda390000 0x35105db 0x39000003 0x5105dc39 0x351 0x5dd3900 0x35105 0xde390000 0x35105df 0x39000003 0x5105e039 0x351 0x5e13900 0x35105 0xe2390000 0x35105e3 0x39000003 0x5105e439 0x351 0x5e53900 0x35105 0xe6390000 0x35105e7 0x39000003 0x5105e839 0x351 0x5e93900 0x35105 0xea390000 0x35105eb 0x39000003 0x5105ec39 0x351 0x5ed3900 0x35105 0xee390000 0x35105ef 0x39000003 0x5105f039 0x351 0x5f13900 0x35105 0xf2390000 0x35105f3 0x39000003 0x5105f439 0x351 0x5f53900 0x35105 0xf6390000 0x35105f7 0x39000003 0x5105f839 0x351 0x5f93900 0x35105 0xfa390000 0x35105fb 0x39000003 0x5105fc39 0x351 0x5fd3900 0x35105 0xfe390000 0x35105ff 0x39000003 0x51060039 0x351 0x6013900 0x35106 0x2390000 0x3510603 0x39000003 0x51060439 0x351 0x6053900 0x35106 0x6390000 0x3510607 0x39000003 0x51060839 0x351 0x6093900 0x35106 0xa390000 0x351060b 0x39000003 0x51060c39 0x351 0x60d3900 0x35106 0xe390000 0x351060f 0x39000003 0x51061039 0x351 0x6113900 0x35106 0x12390000 0x3510613 0x39000003 0x51061439 0x351 0x6153900 0x35106 0x16390000 0x3510617 0x39000003 0x51061839 0x351 0x6193900 0x35106 0x1a390000 0x351061b 0x39000003 0x51061c39 0x351 0x61d3900 0x35106 0x1e390000 0x351061f 0x39000003 0x51062039 0x351 0x6213900 0x35106 0x22390000 0x3510623 0x39000003 0x51062439 0x351 0x6253900 0x35106 0x26390000 0x3510627 0x39000003 0x51062839 0x351 0x6293900 0x35106 0x2a390000 0x351062b 0x39000003 0x51062c39 0x351 0x62d3900 0x35106 0x2e390000 0x351062f 0x39000003 0x51063039 0x351 0x6313900 0x35106 0x32390000 0x3510633 0x39000003 0x51063439 0x351 0x6353900 0x35106 0x36390000 0x3510637 0x39000003 0x51063839 0x351 0x6393900 0x35106 0x3a390000 0x351063b 0x39000003 0x51063c39 0x351 0x63d3900 0x35106 0x3e390000 0x351063f 0x39000003 0x51064039 0x351 0x6413900 0x35106 0x42390000 0x3510643 0x39000003 0x51064439 0x351 0x6453900 0x35106 0x46390000 0x3510647 0x39000003 0x51064839 0x351 0x6493900 0x35106 0x4a390000 0x351064b 0x39000003 0x51064c39 0x351 0x64d3900 0x35106 0x4e390000 0x351064f 0x39000003 0x51065039 0x351 0x6513900 0x35106 0x52390000 0x3510653 0x39000003 0x51065439 0x351 0x6553900 0x35106 0x56390000 0x3510657 0x39000003 0x51065839 0x351 0x6593900 0x35106 0x5a390000 0x351065b 0x39000003 0x51065c39 0x351 0x65d3900 0x35106 0x5e390000 0x351065f 0x39000003 0x51066039 0x351 0x6613900 0x35106 0x62390000 0x3510663 0x39000003 0x51066439 0x351 0x6653900 0x35106 0x66390000 0x3510667 0x39000003 0x51066839 0x351 0x6693900 0x35106 0x6a390000 0x351066b 0x39000003 0x51066c39 0x351 0x66d3900 0x35106 0x6e390000 0x351066f 0x39000003 0x51067039 0x351 0x6713900 0x35106 0x72390000 0x3510673 0x39000003 0x51067439 0x351 0x6753900 0x35106 0x76390000 0x3510677 0x39000003 0x51067839 0x351 0x6793900 0x35106 0x7a390000 0x351067b 0x39000003 0x51067c39 0x351 0x67d3900 0x35106 0x7e390000 0x351067f 0x39000003 0x51068039 0x351 0x6813900 0x35106 0x82390000 0x3510683 0x39000003 0x51068439 0x351 0x6853900 0x35106 0x86390000 0x3510687 0x39000003 0x51068839 0x351 0x6893900 0x35106 0x8a390000 0x351068b 0x39000003 0x51068c39 0x351 0x68d3900 0x35106 0x8e390000 0x351068f 0x39000003 0x51069039 0x351 0x6913900 0x35106 0x92390000 0x3510693 0x39000003 0x51069439 0x351 0x6953900 0x35106 0x96390000 0x3510697 0x39000003 0x51069839 0x351 0x6993900 0x35106 0x9a390000 0x351069b 0x39000003 0x51069c39 0x351 0x69d3900 0x35106 0x9e390000 0x351069f 0x39000003 0x5106a039 0x351 0x6a13900 0x35106 0xa2390000 0x35106a3 0x39000003 0x5106a439 0x351 0x6a53900 0x35106 0xa6390000 0x35106a7 0x39000003 0x5106a839 0x351 0x6a93900 0x35106 0xaa390000 0x35106ab 0x39000003 0x5106ac39 0x351 0x6ad3900 0x35106 0xae390000 0x35106af 0x39000003 0x5106b039 0x351 0x6b13900 0x35106 0xb2390000 0x35106b3 0x39000003 0x5106b439 0x351 0x6b53900 0x35106 0xb6390000 0x35106b7 0x39000003 0x5106b839 0x351 0x6b93900 0x35106 0xba390000 0x35106bb 0x39000003 0x5106bc39 0x351 0x6bd3900 0x35106 0xbe390000 0x35106bf 0x39000003 0x5106c039 0x351 0x6c13900 0x35106 0xc2390000 0x35106c3 0x39000003 0x5106c439 0x351 0x6c53900 0x35106 0xc6390000 0x35106c7 0x39000003 0x5106c839 0x351 0x6c93900 0x35106 0xca390000 0x35106cb 0x39000003 0x5106cc39 0x351 0x6cd3900 0x35106 0xce390000 0x35106cf 0x39000003 0x5106d039 0x351 0x6d13900 0x35106 0xd2390000 0x35106d3 0x39000003 0x5106d439 0x351 0x6d53900 0x35106 0xd6390000 0x35106d7 0x39000003 0x5106d839 0x351 0x6d93900 0x35106 0xda390000 0x35106db 0x39000003 0x5106dc39 0x351 0x6dd3900 0x35106 0xde390000 0x35106df 0x39000003 0x5106e039 0x351 0x6e13900 0x35106 0xe2390000 0x35106e3 0x39000003 0x5106e439 0x351 0x6e53900 0x35106 0xe6390000 0x35106e7 0x39000003 0x5106e839 0x351 0x6e93900 0x35106 0xea390000 0x35106eb 0x39000003 0x5106ec39 0x351 0x6ed3900 0x35106 0xee390000 0x35106ef 0x39000003 0x5106f039 0x351 0x6f13900 0x35106 0xf2390000 0x35106f3 0x39000003 0x5106f439 0x351 0x6f53900 0x35106 0xf6390000 0x35106f7 0x39000003 0x5106f839 0x351 0x6f93900 0x35106 0xfa390000 0x35106fb 0x39000003 0x5106fc39 0x351 0x6fd3900 0x35106 0xfe390000 0x35106ff 0x39000003 0x51070039 0x351 0x7013900 0x35107 0x2390000 0x3510703 0x39000003 0x51070439 0x351 0x7053900 0x35107 0x6390000 0x3510707 0x39000003 0x51070839 0x351 0x7093900 0x35107 0xa390000 0x351070b 0x39000003 0x51070c39 0x351 0x70d3900 0x35107 0xe390000 0x351070f 0x39000003 0x51071039 0x351 0x7113900 0x35107 0x12390000 0x3510713 0x39000003 0x51071439 0x351 0x7153900 0x35107 0x16390000 0x3510717 0x39000003 0x51071839 0x351 0x7193900 0x35107 0x1a390000 0x351071b 0x39000003 0x51071c39 0x351 0x71d3900 0x35107 0x1e390000 0x351071f 0x39000003 0x51072039 0x351 0x7213900 0x35107 0x22390000 0x3510723 0x39000003 0x51072439 0x351 0x7253900 0x35107 0x26390000 0x3510727 0x39000003 0x51072839 0x351 0x7293900 0x35107 0x2a390000 0x351072b 0x39000003 0x51072c39 0x351 0x72d3900 0x35107 0x2e390000 0x351072f 0x39000003 0x51073039 0x351 0x7313900 0x35107 0x32390000 0x3510733 0x39000003 0x51073439 0x351 0x7353900 0x35107 0x36390000 0x3510737 0x39000003 0x51073839 0x351 0x7393900 0x35107 0x3a390000 0x351073b 0x39000003 0x51073c39 0x351 0x73d3900 0x35107 0x3e390000 0x351073f 0x39000003 0x51074039 0x351 0x7413900 0x35107 0x42390000 0x3510743 0x39000003 0x51074439 0x351 0x7453900 0x35107 0x46390000 0x3510747 0x39000003 0x51074839 0x351 0x7493900 0x35107 0x4a390000 0x351074b 0x39000003 0x51074c39 0x351 0x74d3900 0x35107 0x4e390000 0x351074f 0x39000003 0x51075039 0x351 0x7513900 0x35107 0x52390000 0x3510753 0x39000003 0x51075439 0x351 0x7553900 0x35107 0x56390000 0x3510757 0x39000003 0x51075839 0x351 0x7593900 0x35107 0x5a390000 0x351075b 0x39000003 0x51075c39 0x351 0x75d3900 0x35107 0x5e390000 0x351075f 0x39000003 0x51076039 0x351 0x7613900 0x35107 0x62390000 0x3510763 0x39000003 0x51076439 0x351 0x7653900 0x35107 0x66390000 0x3510767 0x39000003 0x51076839 0x351 0x7693900 0x35107 0x6a390000 0x351076b 0x39000003 0x51076c39 0x351 0x76d3900 0x35107 0x6e390000 0x351076f 0x39000003 0x51077039 0x351 0x7713900 0x35107 0x72390000 0x3510773 0x39000003 0x51077439 0x351 0x7753900 0x35107 0x76390000 0x3510777 0x39000003 0x51077839 0x351 0x7793900 0x35107 0x7a390000 0x351077b 0x39000003 0x51077c39 0x351 0x77d3900 0x35107 0x7e390000 0x351077f 0x39000003 0x51078039 0x351 0x7813900 0x35107 0x82390000 0x3510783 0x39000003 0x51078439 0x351 0x7853900 0x35107 0x86390000 0x3510787 0x39000003 0x51078839 0x351 0x7893900 0x35107 0x8a390000 0x351078b 0x39000003 0x51078c39 0x351 0x78d3900 0x35107 0x8e390000 0x351078f 0x39000003 0x51079039 0x351 0x7913900 0x35107 0x92390000 0x3510793 0x39000003 0x51079439 0x351 0x7953900 0x35107 0x96390000 0x3510797 0x39000003 0x51079839 0x351 0x7993900 0x35107 0x9a390000 0x351079b 0x39000003 0x51079c39 0x351 0x79d3900 0x35107 0x9e390000 0x351079f 0x39000003 0x5107a039 0x351 0x7a13900 0x35107 0xa2390000 0x35107a3 0x39000003 0x5107a439 0x351 0x7a53900 0x35107 0xa6390000 0x35107a7 0x39000003 0x5107a839 0x351 0x7a93900 0x35107 0xaa390000 0x35107ab 0x39000003 0x5107ac39 0x351 0x7ad3900 0x35107 0xae390000 0x35107af 0x39000003 0x5107b039 0x351 0x7b13900 0x35107 0xb2390000 0x35107b3 0x39000003 0x5107b439 0x351 0x7b53900 0x35107 0xb6390000 0x35107b7 0x39000003 0x5107b839 0x351 0x7b93900 0x35107 0xba390000 0x35107bb 0x39000003 0x5107bc39 0x351 0x7bd3900 0x35107 0xbe390000 0x35107bf 0x39000003 0x5107c039 0x351 0x7c13900 0x35107 0xc2390000 0x35107c3 0x39000003 0x5107c439 0x351 0x7c53900 0x35107 0xc6390000 0x35107c7 0x39000003 0x5107c839 0x351 0x7c93900 0x35107 0xca390000 0x35107cb 0x39000003 0x5107cc39 0x351 0x7cd3900 0x35107 0xce390000 0x35107cf 0x39000003 0x5107d039 0x351 0x7d13900 0x35107 0xd2390000 0x35107d3 0x39000003 0x5107d439 0x351 0x7d53900 0x35107 0xd6390000 0x35107d7 0x39000003 0x5107d839 0x351 0x7d93900 0x35107 0xda390000 0x35107db 0x39000003 0x5107dc39 0x351 0x7dd3900 0x35107 0xde390000 0x35107df 0x39000003 0x5107e039 0x351 0x7e13900 0x35107 0xe2390000 0x35107e3 0x39000003 0x5107e439 0x351 0x7e53900 0x35107 0xe6390000 0x35107e7 0x39000003 0x5107e839 0x351 0x7e93900 0x35107 0xea390000 0x35107eb 0x39000003 0x5107ec39 0x351 0x7ed3900 0x35107 0xee390000 0x35107ef 0x39000003 0x5107f039 0x351 0x7f13900 0x35107 0xf2390000 0x35107f3 0x39000003 0x5107f439 0x351 0x7f53900 0x35107 0xf6390000 0x35107f7 0x39000003 0x5107f839 0x351 0x7f93900 0x35107 0xfa390000 0x35107fb 0x39000003 0x5107fc39 0x351 0x7fd3900 0x35107 0xfe390000 0x35107ff 0x39000003 0x51080039 0x351 0x8013900 0x35108 0x2390000 0x3510803 0x39000003 0x51080439 0x351 0x8053900 0x35108 0x6390000 0x3510807 0x39000003 0x51080839 0x351 0x8093900 0x35108 0xa390000 0x351080b 0x39000003 0x51080c39 0x351 0x80d3900 0x35108 0xe390000 0x351080f 0x39000003 0x51081039 0x351 0x8113900 0x35108 0x12390000 0x3510813 0x39000003 0x51081439 0x351 0x8153900 0x35108 0x16390000 0x3510817 0x39000003 0x51081839 0x351 0x8193900 0x35108 0x1a390000 0x351081b 0x39000003 0x51081c39 0x351 0x81d3900 0x35108 0x1e390000 0x351081f 0x39000003 0x51082039 0x351 0x8213900 0x35108 0x22390000 0x3510823 0x39000003 0x51082439 0x351 0x8253900 0x35108 0x26390000 0x3510827 0x39000003 0x51082839 0x351 0x8293900 0x35108 0x2a390000 0x351082b 0x39000003 0x51082c39 0x351 0x82d3900 0x35108 0x2e390000 0x351082f 0x39000003 0x51083039 0x351 0x8313900 0x35108 0x32390000 0x3510833 0x39000003 0x51083439 0x351 0x8353900 0x35108 0x36390000 0x3510837 0x39000003 0x51083839 0x351 0x8393900 0x35108 0x3a390000 0x351083b 0x39000003 0x51083c39 0x351 0x83d3900 0x35108 0x3e390000 0x351083f 0x39000003 0x51084039 0x351 0x8413900 0x35108 0x42390000 0x3510843 0x39000003 0x51084439 0x351 0x8453900 0x35108 0x46390000 0x3510847 0x39000003 0x51084839 0x351 0x8493900 0x35108 0x4a390000 0x351084b 0x39000003 0x51084c39 0x351 0x84d3900 0x35108 0x4e390000 0x351084f 0x39000003 0x51085039 0x351 0x8513900 0x35108 0x52390000 0x3510853 0x39000003 0x51085439 0x351 0x8553900 0x35108 0x56390000 0x3510857 0x39000003 0x51085839 0x351 0x8593900 0x35108 0x5a390000 0x351085b 0x39000003 0x51085c39 0x351 0x85d3900 0x35108 0x5e390000 0x351085f 0x39000003 0x51086039 0x351 0x8613900 0x35108 0x62390000 0x3510863 0x39000003 0x51086439 0x351 0x8653900 0x35108 0x66390000 0x3510867 0x39000003 0x51086839 0x351 0x8693900 0x35108 0x6a390000 0x351086b 0x39000003 0x51086c39 0x351 0x86d3900 0x35108 0x6e390000 0x351086f 0x39000003 0x51087039 0x351 0x8713900 0x35108 0x72390000 0x3510873 0x39000003 0x51087439 0x351 0x8753900 0x35108 0x76390000 0x3510877 0x39000003 0x51087839 0x351 0x8793900 0x35108 0x7a390000 0x351087b 0x39000003 0x51087c39 0x351 0x87d3900 0x35108 0x7e390000 0x351087f 0x39000003 0x51088039 0x351 0x8813900 0x35108 0x82390000 0x3510883 0x39000003 0x51088439 0x351 0x8853900 0x35108 0x86390000 0x3510887 0x39000003 0x51088839 0x351 0x8893900 0x35108 0x8a390000 0x351088b 0x39000003 0x51088c39 0x351 0x88d3900 0x35108 0x8e390000 0x351088f 0x39000003 0x51089039 0x351 0x8913900 0x35108 0x92390000 0x3510893 0x39000003 0x51089439 0x351 0x8953900 0x35108 0x96390000 0x3510897 0x39000003 0x51089839 0x351 0x8993900 0x35108 0x9a390000 0x351089b 0x39000003 0x51089c39 0x351 0x89d3900 0x35108 0x9e390000 0x351089f 0x39000003 0x5108a039 0x351 0x8a13900 0x35108 0xa2390000 0x35108a3 0x39000003 0x5108a439 0x351 0x8a53900 0x35108 0xa6390000 0x35108a7 0x39000003 0x5108a839 0x351 0x8a93900 0x35108 0xaa390000 0x35108ab 0x39000003 0x5108ac39 0x351 0x8ad3900 0x35108 0xae390000 0x35108af 0x39000003 0x5108b039 0x351 0x8b13900 0x35108 0xb2390000 0x35108b3 0x39000003 0x5108b439 0x351 0x8b53900 0x35108 0xb6390000 0x35108b7 0x39000003 0x5108b839 0x351 0x8b93900 0x35108 0xba390000 0x35108bb 0x39000003 0x5108bc39 0x351 0x8bd3900 0x35108 0xbe390000 0x35108bf 0x39000003 0x5108c039 0x351 0x8c13900 0x35108 0xc2390000 0x35108c3 0x39000003 0x5108c439 0x351 0x8c53900 0x35108 0xc6390000 0x35108c7 0x39000003 0x5108c839 0x351 0x8c93900 0x35108 0xca390000 0x35108cb 0x39000003 0x5108cc39 0x351 0x8cd3900 0x35108 0xce390000 0x35108cf 0x39000003 0x5108d039 0x351 0x8d13900 0x35108 0xd2390000 0x35108d3 0x39000003 0x5108d439 0x351 0x8d53900 0x35108 0xd6390000 0x35108d7 0x39000003 0x5108d839 0x351 0x8d93900 0x35108 0xda390000 0x35108db 0x39000003 0x5108dc39 0x351 0x8dd3900 0x35108 0xde390000 0x35108df 0x39000003 0x5108e039 0x351 0x8e13900 0x35108 0xe2390000 0x35108e3 0x39000003 0x5108e439 0x351 0x8e53900 0x35108 0xe6390000 0x35108e7 0x39000003 0x5108e839 0x351 0x8e93900 0x35108 0xea390000 0x35108eb 0x39000003 0x5108ec39 0x351 0x8ed3900 0x35108 0xee390000 0x35108ef 0x39000003 0x5108f039 0x351 0x8f13900 0x35108 0xf2390000 0x35108f3 0x39000003 0x5108f439 0x351 0x8f53900 0x35108 0xf6390000 0x35108f7 0x39000003 0x5108f839 0x351 0x8f93900 0x35108 0xfa390000 0x35108fb 0x39000003 0x5108fc39 0x351 0x8fd3900 0x35108 0xfe390000 0x35108ff 0x39000003 0x51090039 0x351 0x9013900 0x35109 0x2390000 0x3510903 0x39000003 0x51090439 0x351 0x9053900 0x35109 0x6390000 0x3510907 0x39000003 0x51090839 0x351 0x9093900 0x35109 0xa390000 0x351090b 0x39000003 0x51090c39 0x351 0x90d3900 0x35109 0xe390000 0x351090f 0x39000003 0x51091039 0x351 0x9113900 0x35109 0x12390000 0x3510913 0x39000003 0x51091439 0x351 0x9153900 0x35109 0x16390000 0x3510917 0x39000003 0x51091839 0x351 0x9193900 0x35109 0x1a390000 0x351091b 0x39000003 0x51091c39 0x351 0x91d3900 0x35109 0x1e390000 0x351091f 0x39000003 0x51092039 0x351 0x9213900 0x35109 0x22390000 0x3510923 0x39000003 0x51092439 0x351 0x9253900 0x35109 0x26390000 0x3510927 0x39000003 0x51092839 0x351 0x9293900 0x35109 0x2a390000 0x351092b 0x39000003 0x51092c39 0x351 0x92d3900 0x35109 0x2e390000 0x351092f 0x39000003 0x51093039 0x351 0x9313900 0x35109 0x32390000 0x3510933 0x39000003 0x51093439 0x351 0x9353900 0x35109 0x36390000 0x3510937 0x39000003 0x51093839 0x351 0x9393900 0x35109 0x3a390000 0x351093b 0x39000003 0x51093c39 0x351 0x93d3900 0x35109 0x3e390000 0x351093f 0x39000003 0x51094039 0x351 0x9413900 0x35109 0x42390000 0x3510943 0x39000003 0x51094439 0x351 0x9453900 0x35109 0x46390000 0x3510947 0x39000003 0x51094839 0x351 0x9493900 0x35109 0x4a390000 0x351094b 0x39000003 0x51094c39 0x351 0x94d3900 0x35109 0x4e390000 0x351094f 0x39000003 0x51095039 0x351 0x9513900 0x35109 0x52390000 0x3510953 0x39000003 0x51095439 0x351 0x9553900 0x35109 0x56390000 0x3510957 0x39000003 0x51095839 0x351 0x9593900 0x35109 0x5a390000 0x351095b 0x39000003 0x51095c39 0x351 0x95d3900 0x35109 0x5e390000 0x351095f 0x39000003 0x51096039 0x351 0x9613900 0x35109 0x62390000 0x3510963 0x39000003 0x51096439 0x351 0x9653900 0x35109 0x66390000 0x3510967 0x39000003 0x51096839 0x351 0x9693900 0x35109 0x6a390000 0x351096b 0x39000003 0x51096c39 0x351 0x96d3900 0x35109 0x6e390000 0x351096f 0x39000003 0x51097039 0x351 0x9713900 0x35109 0x72390000 0x3510973 0x39000003 0x51097439 0x351 0x9753900 0x35109 0x76390000 0x3510977 0x39000003 0x51097839 0x351 0x9793900 0x35109 0x7a390000 0x351097b 0x39000003 0x51097c39 0x351 0x97d3900 0x35109 0x7e390000 0x351097f 0x39000003 0x51098039 0x351 0x9813900 0x35109 0x82390000 0x3510983 0x39000003 0x51098439 0x351 0x9853900 0x35109 0x86390000 0x3510987 0x39000003 0x51098839 0x351 0x9893900 0x35109 0x8a390000 0x351098b 0x39000003 0x51098c39 0x351 0x98d3900 0x35109 0x8e390000 0x351098f 0x39000003 0x51099039 0x351 0x9913900 0x35109 0x92390000 0x3510993 0x39000003 0x51099439 0x351 0x9953900 0x35109 0x96390000 0x3510997 0x39000003 0x51099839 0x351 0x9993900 0x35109 0x9a390000 0x351099b 0x39000003 0x51099c39 0x351 0x99d3900 0x35109 0x9e390000 0x351099f 0x39000003 0x5109a039 0x351 0x9a13900 0x35109 0xa2390000 0x35109a3 0x39000003 0x5109a439 0x351 0x9a53900 0x35109 0xa6390000 0x35109a7 0x39000003 0x5109a839 0x351 0x9a93900 0x35109 0xaa390000 0x35109ab 0x39000003 0x5109ac39 0x351 0x9ad3900 0x35109 0xae390000 0x35109af 0x39000003 0x5109b039 0x351 0x9b13900 0x35109 0xb2390000 0x35109b3 0x39000003 0x5109b439 0x351 0x9b53900 0x35109 0xb6390000 0x35109b7 0x39000003 0x5109b839 0x351 0x9b93900 0x35109 0xba390000 0x35109bb 0x39000003 0x5109bc39 0x351 0x9bd3900 0x35109 0xbe390000 0x35109bf 0x39000003 0x5109c039 0x351 0x9c13900 0x35109 0xc2390000 0x35109c3 0x39000003 0x5109c439 0x351 0x9c53900 0x35109 0xc6390000 0x35109c7 0x39000003 0x5109c839 0x351 0x9c93900 0x35109 0xca390000 0x35109cb 0x39000003 0x5109cc39 0x351 0x9cd3900 0x35109 0xce390000 0x35109cf 0x39000003 0x5109d039 0x351 0x9d13900 0x35109 0xd2390000 0x35109d3 0x39000003 0x5109d439 0x351 0x9d53900 0x35109 0xd6390000 0x35109d7 0x39000003 0x5109d839 0x351 0x9d93900 0x35109 0xda390000 0x35109db 0x39000003 0x5109dc39 0x351 0x9dd3900 0x35109 0xde390000 0x35109df 0x39000003 0x5109e039 0x351 0x9e13900 0x35109 0xe2390000 0x35109e3 0x39000003 0x5109e439 0x351 0x9e53900 0x35109 0xe6390000 0x35109e7 0x39000003 0x5109e839 0x351 0x9e93900 0x35109 0xea390000 0x35109eb 0x39000003 0x5109ec39 0x351 0x9ed3900 0x35109 0xee390000 0x35109ef 0x39000003 0x5109f039 0x351 0x9f13900 0x35109 0xf2390000 0x35109f3 0x39000003 0x5109f439 0x351 0x9f53900 0x35109 0xf6390000 0x35109f7 0x39000003 0x5109f839 0x351 0x9f93900 0x35109 0xfa390000 0x35109fb 0x39000003 0x5109fc39 0x351 0x9fd3900 0x35109 0xfe390000 0x35109ff 0x39000003 0x510a0039 0x351 0xa013900 0x3510a 0x2390000 0x3510a03 0x39000003 0x510a0439 0x351 0xa053900 0x3510a 0x6390000 0x3510a07 0x39000003 0x510a0839 0x351 0xa093900 0x3510a 0xa390000 0x3510a0b 0x39000003 0x510a0c39 0x351 0xa0d3900 0x3510a 0xe390000 0x3510a0f 0x39000003 0x510a1039 0x351 0xa113900 0x3510a 0x12390000 0x3510a13 0x39000003 0x510a1439 0x351 0xa153900 0x3510a 0x16390000 0x3510a17 0x39000003 0x510a1839 0x351 0xa193900 0x3510a 0x1a390000 0x3510a1b 0x39000003 0x510a1c39 0x351 0xa1d3900 0x3510a 0x1e390000 0x3510a1f 0x39000003 0x510a2039 0x351 0xa213900 0x3510a 0x22390000 0x3510a23 0x39000003 0x510a2439 0x351 0xa253900 0x3510a 0x26390000 0x3510a27 0x39000003 0x510a2839 0x351 0xa293900 0x3510a 0x2a390000 0x3510a2b 0x39000003 0x510a2c39 0x351 0xa2d3900 0x3510a 0x2e390000 0x3510a2f 0x39000003 0x510a3039 0x351 0xa313900 0x3510a 0x32390000 0x3510a33 0x39000003 0x510a3439 0x351 0xa353900 0x3510a 0x36390000 0x3510a37 0x39000003 0x510a3839 0x351 0xa393900 0x3510a 0x3a390000 0x3510a3b 0x39000003 0x510a3c39 0x351 0xa3d3900 0x3510a 0x3e390000 0x3510a3f 0x39000003 0x510a4039 0x351 0xa413900 0x3510a 0x42390000 0x3510a43 0x39000003 0x510a4439 0x351 0xa453900 0x3510a 0x46390000 0x3510a47 0x39000003 0x510a4839 0x351 0xa493900 0x3510a 0x4a390000 0x3510a4b 0x39000003 0x510a4c39 0x351 0xa4d3900 0x3510a 0x4e390000 0x3510a4f 0x39000003 0x510a5039 0x351 0xa513900 0x3510a 0x52390000 0x3510a53 0x39000003 0x510a5439 0x351 0xa553900 0x3510a 0x56390000 0x3510a57 0x39000003 0x510a5839 0x351 0xa593900 0x3510a 0x5a390000 0x3510a5b 0x39000003 0x510a5c39 0x351 0xa5d3900 0x3510a 0x5e390000 0x3510a5f 0x39000003 0x510a6039 0x351 0xa613900 0x3510a 0x62390000 0x3510a63 0x39000003 0x510a6439 0x351 0xa653900 0x3510a 0x66390000 0x3510a67 0x39000003 0x510a6839 0x351 0xa693900 0x3510a 0x6a390000 0x3510a6b 0x39000003 0x510a6c39 0x351 0xa6d3900 0x3510a 0x6e390000 0x3510a6f 0x39000003 0x510a7039 0x351 0xa713900 0x3510a 0x72390000 0x3510a73 0x39000003 0x510a7439 0x351 0xa753900 0x3510a 0x76390000 0x3510a77 0x39000003 0x510a7839 0x351 0xa793900 0x3510a 0x7a390000 0x3510a7b 0x39000003 0x510a7c39 0x351 0xa7d3900 0x3510a 0x7e390000 0x3510a7f 0x39000003 0x510a8039 0x351 0xa813900 0x3510a 0x82390000 0x3510a83 0x39000003 0x510a8439 0x351 0xa853900 0x3510a 0x86390000 0x3510a87 0x39000003 0x510a8839 0x351 0xa893900 0x3510a 0x8a390000 0x3510a8b 0x39000003 0x510a8c39 0x351 0xa8d3900 0x3510a 0x8e390000 0x3510a8f 0x39000003 0x510a9039 0x351 0xa913900 0x3510a 0x92390000 0x3510a93 0x39000003 0x510a9439 0x351 0xa953900 0x3510a 0x96390000 0x3510a97 0x39000003 0x510a9839 0x351 0xa993900 0x3510a 0x9a390000 0x3510a9b 0x39000003 0x510a9c39 0x351 0xa9d3900 0x3510a 0x9e390000 0x3510a9f 0x39000003 0x510aa039 0x351 0xaa13900 0x3510a 0xa2390000 0x3510aa3 0x39000003 0x510aa439 0x351 0xaa53900 0x3510a 0xa6390000 0x3510aa7 0x39000003 0x510aa839 0x351 0xaa93900 0x3510a 0xaa390000 0x3510aab 0x39000003 0x510aac39 0x351 0xaad3900 0x3510a 0xae390000 0x3510aaf 0x39000003 0x510ab039 0x351 0xab13900 0x3510a 0xb2390000 0x3510ab3 0x39000003 0x510ab439 0x351 0xab53900 0x3510a 0xb6390000 0x3510ab7 0x39000003 0x510ab839 0x351 0xab93900 0x3510a 0xba390000 0x3510abb 0x39000003 0x510abc39 0x351 0xabd3900 0x3510a 0xbe390000 0x3510abf 0x39000003 0x510ac039 0x351 0xac13900 0x3510a 0xc2390000 0x3510ac3 0x39000003 0x510ac439 0x351 0xac53900 0x3510a 0xc6390000 0x3510ac7 0x39000003 0x510ac839 0x351 0xac93900 0x3510a 0xca390000 0x3510acb 0x39000003 0x510acc39 0x351 0xacd3900 0x3510a 0xce390000 0x3510acf 0x39000003 0x510ad039 0x351 0xad13900 0x3510a 0xd2390000 0x3510ad3 0x39000003 0x510ad439 0x351 0xad53900 0x3510a 0xd6390000 0x3510ad7 0x39000003 0x510ad839 0x351 0xad93900 0x3510a 0xda390000 0x3510adb 0x39000003 0x510adc39 0x351 0xadd3900 0x3510a 0xde390000 0x3510adf 0x39000003 0x510ae039 0x351 0xae13900 0x3510a 0xe2390000 0x3510ae3 0x39000003 0x510ae439 0x351 0xae53900 0x3510a 0xe6390000 0x3510ae7 0x39000003 0x510ae839 0x351 0xae93900 0x3510a 0xea390000 0x3510aeb 0x39000003 0x510aec39 0x351 0xaed3900 0x3510a 0xee390000 0x3510aef 0x39000003 0x510af039 0x351 0xaf13900 0x3510a 0xf2390000 0x3510af3 0x39000003 0x510af439 0x351 0xaf53900 0x3510a 0xf6390000 0x3510af7 0x39000003 0x510af839 0x351 0xaf93900 0x3510a 0xfa390000 0x3510afb 0x39000003 0x510afc39 0x351 0xafd3900 0x3510a 0xfe390000 0x3510aff 0x39000003 0x510b0039 0x351 0xb013900 0x3510b 0x2390000 0x3510b03 0x39000003 0x510b0439 0x351 0xb053900 0x3510b 0x6390000 0x3510b07 0x39000003 0x510b0839 0x351 0xb093900 0x3510b 0xa390000 0x3510b0b 0x39000003 0x510b0c39 0x351 0xb0d3900 0x3510b 0xe390000 0x3510b0f 0x39000003 0x510b1039 0x351 0xb113900 0x3510b 0x12390000 0x3510b13 0x39000003 0x510b1439 0x351 0xb153900 0x3510b 0x16390000 0x3510b17 0x39000003 0x510b1839 0x351 0xb193900 0x3510b 0x1a390000 0x3510b1b 0x39000003 0x510b1c39 0x351 0xb1d3900 0x3510b 0x1e390000 0x3510b1f 0x39000003 0x510b2039 0x351 0xb213900 0x3510b 0x22390000 0x3510b23 0x39000003 0x510b2439 0x351 0xb253900 0x3510b 0x26390000 0x3510b27 0x39000003 0x510b2839 0x351 0xb293900 0x3510b 0x2a390000 0x3510b2b 0x39000003 0x510b2c39 0x351 0xb2d3900 0x3510b 0x2e390000 0x3510b2f 0x39000003 0x510b3039 0x351 0xb313900 0x3510b 0x32390000 0x3510b33 0x39000003 0x510b3439 0x351 0xb353900 0x3510b 0x36390000 0x3510b37 0x39000003 0x510b3839 0x351 0xb393900 0x3510b 0x3a390000 0x3510b3b 0x39000003 0x510b3c39 0x351 0xb3d3900 0x3510b 0x3e390000 0x3510b3f 0x39000003 0x510b4039 0x351 0xb413900 0x3510b 0x42390000 0x3510b43 0x39000003 0x510b4439 0x351 0xb453900 0x3510b 0x46390000 0x3510b47 0x39000003 0x510b4839 0x351 0xb493900 0x3510b 0x4a390000 0x3510b4b 0x39000003 0x510b4c39 0x351 0xb4d3900 0x3510b 0x4e390000 0x3510b4f 0x39000003 0x510b5039 0x351 0xb513900 0x3510b 0x52390000 0x3510b53 0x39000003 0x510b5439 0x351 0xb553900 0x3510b 0x56390000 0x3510b57 0x39000003 0x510b5839 0x351 0xb593900 0x3510b 0x5a390000 0x3510b5b 0x39000003 0x510b5c39 0x351 0xb5d3900 0x3510b 0x5e390000 0x3510b5f 0x39000003 0x510b6039 0x351 0xb613900 0x3510b 0x62390000 0x3510b63 0x39000003 0x510b6439 0x351 0xb653900 0x3510b 0x66390000 0x3510b67 0x39000003 0x510b6839 0x351 0xb693900 0x3510b 0x6a390000 0x3510b6b 0x39000003 0x510b6c39 0x351 0xb6d3900 0x3510b 0x6e390000 0x3510b6f 0x39000003 0x510b7039 0x351 0xb713900 0x3510b 0x72390000 0x3510b73 0x39000003 0x510b7439 0x351 0xb753900 0x3510b 0x76390000 0x3510b77 0x39000003 0x510b7839 0x351 0xb793900 0x3510b 0x7a390000 0x3510b7b 0x39000003 0x510b7c39 0x351 0xb7d3900 0x3510b 0x7e390000 0x3510b7f 0x39000003 0x510b8039 0x351 0xb813900 0x3510b 0x82390000 0x3510b83 0x39000003 0x510b8439 0x351 0xb853900 0x3510b 0x86390000 0x3510b87 0x39000003 0x510b8839 0x351 0xb893900 0x3510b 0x8a390000 0x3510b8b 0x39000003 0x510b8c39 0x351 0xb8d3900 0x3510b 0x8e390000 0x3510b8f 0x39000003 0x510b9039 0x351 0xb913900 0x3510b 0x92390000 0x3510b93 0x39000003 0x510b9439 0x351 0xb953900 0x3510b 0x96390000 0x3510b97 0x39000003 0x510b9839 0x351 0xb993900 0x3510b 0x9a390000 0x3510b9b 0x39000003 0x510b9c39 0x351 0xb9d3900 0x3510b 0x9e390000 0x3510b9f 0x39000003 0x510ba039 0x351 0xba13900 0x3510b 0xa2390000 0x3510ba3 0x39000003 0x510ba439 0x351 0xba53900 0x3510b 0xa6390000 0x3510ba7 0x39000003 0x510ba839 0x351 0xba93900 0x3510b 0xaa390000 0x3510bab 0x39000003 0x510bac39 0x351 0xbad3900 0x3510b 0xae390000 0x3510baf 0x39000003 0x510bb039 0x351 0xbb13900 0x3510b 0xb2390000 0x3510bb3 0x39000003 0x510bb439 0x351 0xbb53900 0x3510b 0xb6390000 0x3510bb7 0x39000003 0x510bb839 0x351 0xbb93900 0x3510b 0xba390000 0x3510bbb 0x39000003 0x510bbc39 0x351 0xbbd3900 0x3510b 0xbe390000 0x3510bbf 0x39000003 0x510bc039 0x351 0xbc13900 0x3510b 0xc2390000 0x3510bc3 0x39000003 0x510bc439 0x351 0xbc53900 0x3510b 0xc6390000 0x3510bc7 0x39000003 0x510bc839 0x351 0xbc93900 0x3510b 0xca390000 0x3510bcb 0x39000003 0x510bcc39 0x351 0xbcd3900 0x3510b 0xce390000 0x3510bcf 0x39000003 0x510bd039 0x351 0xbd13900 0x3510b 0xd2390000 0x3510bd3 0x39000003 0x510bd439 0x351 0xbd53900 0x3510b 0xd6390000 0x3510bd7 0x39000003 0x510bd839 0x351 0xbd93900 0x3510b 0xda390000 0x3510bdb 0x39000003 0x510bdc39 0x351 0xbdd3900 0x3510b 0xde390000 0x3510bdf 0x39000003 0x510be039 0x351 0xbe13900 0x3510b 0xe2390000 0x3510be3 0x39000003 0x510be439 0x351 0xbe53900 0x3510b 0xe6390000 0x3510be7 0x39000003 0x510be839 0x351 0xbe93900 0x3510b 0xea390000 0x3510beb 0x39000003 0x510bec39 0x351 0xbed3900 0x3510b 0xee390000 0x3510bef 0x39000003 0x510bf039 0x351 0xbf13900 0x3510b 0xf2390000 0x3510bf3 0x39000003 0x510bf439 0x351 0xbf53900 0x3510b 0xf6390000 0x3510bf7 0x39000003 0x510bf839 0x351 0xbf93900 0x3510b 0xfa390000 0x3510bfb 0x39000003 0x510bfc39 0x351 0xbfd3900 0x3510b 0xfe390000 0x3510bff 0x39000003 0x510c0039 0x351 0xc013900 0x3510c 0x2390000 0x3510c03 0x39000003 0x510c0439 0x351 0xc053900 0x3510c 0x6390000 0x3510c07 0x39000003 0x510c0839 0x351 0xc093900 0x3510c 0xa390000 0x3510c0b 0x39000003 0x510c0c39 0x351 0xc0d3900 0x3510c 0xe390000 0x3510c0f 0x39000003 0x510c1039 0x351 0xc113900 0x3510c 0x12390000 0x3510c13 0x39000003 0x510c1439 0x351 0xc153900 0x3510c 0x16390000 0x3510c17 0x39000003 0x510c1839 0x351 0xc193900 0x3510c 0x1a390000 0x3510c1b 0x39000003 0x510c1c39 0x351 0xc1d3900 0x3510c 0x1e390000 0x3510c1f 0x39000003 0x510c2039 0x351 0xc213900 0x3510c 0x22390000 0x3510c23 0x39000003 0x510c2439 0x351 0xc253900 0x3510c 0x26390000 0x3510c27 0x39000003 0x510c2839 0x351 0xc293900 0x3510c 0x2a390000 0x3510c2b 0x39000003 0x510c2c39 0x351 0xc2d3900 0x3510c 0x2e390000 0x3510c2f 0x39000003 0x510c3039 0x351 0xc313900 0x3510c 0x32390000 0x3510c33 0x39000003 0x510c3439 0x351 0xc353900 0x3510c 0x36390000 0x3510c37 0x39000003 0x510c3839 0x351 0xc393900 0x3510c 0x3a390000 0x3510c3b 0x39000003 0x510c3c39 0x351 0xc3d3900 0x3510c 0x3e390000 0x3510c3f 0x39000003 0x510c4039 0x351 0xc413900 0x3510c 0x42390000 0x3510c43 0x39000003 0x510c4439 0x351 0xc453900 0x3510c 0x46390000 0x3510c47 0x39000003 0x510c4839 0x351 0xc493900 0x3510c 0x4a390000 0x3510c4b 0x39000003 0x510c4c39 0x351 0xc4d3900 0x3510c 0x4e390000 0x3510c4f 0x39000003 0x510c5039 0x351 0xc513900 0x3510c 0x52390000 0x3510c53 0x39000003 0x510c5439 0x351 0xc553900 0x3510c 0x56390000 0x3510c57 0x39000003 0x510c5839 0x351 0xc593900 0x3510c 0x5a390000 0x3510c5b 0x39000003 0x510c5c39 0x351 0xc5d3900 0x3510c 0x5e390000 0x3510c5f 0x39000003 0x510c6039 0x351 0xc613900 0x3510c 0x62390000 0x3510c63 0x39000003 0x510c6439 0x351 0xc653900 0x3510c 0x66390000 0x3510c67 0x39000003 0x510c6839 0x351 0xc693900 0x3510c 0x6a390000 0x3510c6b 0x39000003 0x510c6c39 0x351 0xc6d3900 0x3510c 0x6e390000 0x3510c6f 0x39000003 0x510c7039 0x351 0xc713900 0x3510c 0x72390000 0x3510c73 0x39000003 0x510c7439 0x351 0xc753900 0x3510c 0x76390000 0x3510c77 0x39000003 0x510c7839 0x351 0xc793900 0x3510c 0x7a390000 0x3510c7b 0x39000003 0x510c7c39 0x351 0xc7d3900 0x3510c 0x7e390000 0x3510c7f 0x39000003 0x510c8039 0x351 0xc813900 0x3510c 0x82390000 0x3510c83 0x39000003 0x510c8439 0x351 0xc853900 0x3510c 0x86390000 0x3510c87 0x39000003 0x510c8839 0x351 0xc893900 0x3510c 0x8a390000 0x3510c8b 0x39000003 0x510c8c39 0x351 0xc8d3900 0x3510c 0x8e390000 0x3510c8f 0x39000003 0x510c9039 0x351 0xc913900 0x3510c 0x92390000 0x3510c93 0x39000003 0x510c9439 0x351 0xc953900 0x3510c 0x96390000 0x3510c97 0x39000003 0x510c9839 0x351 0xc993900 0x3510c 0x9a390000 0x3510c9b 0x39000003 0x510c9c39 0x351 0xc9d3900 0x3510c 0x9e390000 0x3510c9f 0x39000003 0x510ca039 0x351 0xca13900 0x3510c 0xa2390000 0x3510ca3 0x39000003 0x510ca439 0x351 0xca53900 0x3510c 0xa6390000 0x3510ca7 0x39000003 0x510ca839 0x351 0xca93900 0x3510c 0xaa390000 0x3510cab 0x39000003 0x510cac39 0x351 0xcad3900 0x3510c 0xae390000 0x3510caf 0x39000003 0x510cb039 0x351 0xcb13900 0x3510c 0xb2390000 0x3510cb3 0x39000003 0x510cb439 0x351 0xcb53900 0x3510c 0xb6390000 0x3510cb7 0x39000003 0x510cb839 0x351 0xcb93900 0x3510c 0xba390000 0x3510cbb 0x39000003 0x510cbc39 0x351 0xcbd3900 0x3510c 0xbe390000 0x3510cbf 0x39000003 0x510cc039 0x351 0xcc13900 0x3510c 0xc2390000 0x3510cc3 0x39000003 0x510cc439 0x351 0xcc53900 0x3510c 0xc6390000 0x3510cc7 0x39000003 0x510cc839 0x351 0xcc93900 0x3510c 0xca390000 0x3510ccb 0x39000003 0x510ccc39 0x351 0xccd3900 0x3510c 0xce390000 0x3510ccf 0x39000003 0x510cd039 0x351 0xcd13900 0x3510c 0xd2390000 0x3510cd3 0x39000003 0x510cd439 0x351 0xcd53900 0x3510c 0xd6390000 0x3510cd7 0x39000003 0x510cd839 0x351 0xcd93900 0x3510c 0xda390000 0x3510cdb 0x39000003 0x510cdc39 0x351 0xcdd3900 0x3510c 0xde390000 0x3510cdf 0x39000003 0x510ce039 0x351 0xce13900 0x3510c 0xe2390000 0x3510ce3 0x39000003 0x510ce439 0x351 0xce53900 0x3510c 0xe6390000 0x3510ce7 0x39000003 0x510ce839 0x351 0xce93900 0x3510c 0xea390000 0x3510ceb 0x39000003 0x510cec39 0x351 0xced3900 0x3510c 0xee390000 0x3510cef 0x39000003 0x510cf039 0x351 0xcf13900 0x3510c 0xf2390000 0x3510cf3 0x39000003 0x510cf439 0x351 0xcf53900 0x3510c 0xf6390000 0x3510cf7 0x39000003 0x510cf839 0x351 0xcf93900 0x3510c 0xfa390000 0x3510cfb 0x39000003 0x510cfc39 0x351 0xcfd3900 0x3510c 0xfe390000 0x3510cff 0x39000003 0x510d0039 0x351 0xd013900 0x3510d 0x2390000 0x3510d03 0x39000003 0x510d0439 0x351 0xd053900 0x3510d 0x6390000 0x3510d07 0x39000003 0x510d0839 0x351 0xd093900 0x3510d 0xa390000 0x3510d0b 0x39000003 0x510d0c39 0x351 0xd0d3900 0x3510d 0xe390000 0x3510d0f 0x39000003 0x510d1039 0x351 0xd113900 0x3510d 0x12390000 0x3510d13 0x39000003 0x510d1439 0x351 0xd153900 0x3510d 0x16390000 0x3510d17 0x39000003 0x510d1839 0x351 0xd193900 0x3510d 0x1a390000 0x3510d1b 0x39000003 0x510d1c39 0x351 0xd1d3900 0x3510d 0x1e390000 0x3510d1f 0x39000003 0x510d2039 0x351 0xd213900 0x3510d 0x22390000 0x3510d23 0x39000003 0x510d2439 0x351 0xd253900 0x3510d 0x26390000 0x3510d27 0x39000003 0x510d2839 0x351 0xd293900 0x3510d 0x2a390000 0x3510d2b 0x39000003 0x510d2c39 0x351 0xd2d3900 0x3510d 0x2e390000 0x3510d2f 0x39000003 0x510d3039 0x351 0xd313900 0x3510d 0x32390000 0x3510d33 0x39000003 0x510d3439 0x351 0xd353900 0x3510d 0x36390000 0x3510d37 0x39000003 0x510d3839 0x351 0xd393900 0x3510d 0x3a390000 0x3510d3b 0x39000003 0x510d3c39 0x351 0xd3d3900 0x3510d 0x3e390000 0x3510d3f 0x39000003 0x510d4039 0x351 0xd413900 0x3510d 0x42390000 0x3510d43 0x39000003 0x510d4439 0x351 0xd453900 0x3510d 0x46390000 0x3510d47 0x39000003 0x510d4839 0x351 0xd493900 0x3510d 0x4a390000 0x3510d4b 0x39000003 0x510d4c39 0x351 0xd4d3900 0x3510d 0x4e390000 0x3510d4f 0x39000003 0x510d5039 0x351 0xd513900 0x3510d 0x52390000 0x3510d53 0x39000003 0x510d5439 0x351 0xd553900 0x3510d 0x56390000 0x3510d57 0x39000003 0x510d5839 0x351 0xd593900 0x3510d 0x5a390000 0x3510d5b 0x39000003 0x510d5c39 0x351 0xd5d3900 0x3510d 0x5e390000 0x3510d5f 0x39000003 0x510d6039 0x351 0xd613900 0x3510d 0x62390000 0x3510d63 0x39000003 0x510d6439 0x351 0xd653900 0x3510d 0x66390000 0x3510d67 0x39000003 0x510d6839 0x351 0xd693900 0x3510d 0x6a390000 0x3510d6b 0x39000003 0x510d6c39 0x351 0xd6d3900 0x3510d 0x6e390000 0x3510d6f 0x39000003 0x510d7039 0x351 0xd713900 0x3510d 0x72390000 0x3510d73 0x39000003 0x510d7439 0x351 0xd753900 0x3510d 0x76390000 0x3510d77 0x39000003 0x510d7839 0x351 0xd793900 0x3510d 0x7a390000 0x3510d7b 0x39000003 0x510d7c39 0x351 0xd7d3900 0x3510d 0x7e390000 0x3510d7f 0x39000003 0x510d8039 0x351 0xd813900 0x3510d 0x82390000 0x3510d83 0x39000003 0x510d8439 0x351 0xd853900 0x3510d 0x86390000 0x3510d87 0x39000003 0x510d8839 0x351 0xd893900 0x3510d 0x8a390000 0x3510d8b 0x39000003 0x510d8c39 0x351 0xd8d3900 0x3510d 0x8e390000 0x3510d8f 0x39000003 0x510d9039 0x351 0xd913900 0x3510d 0x92390000 0x3510d93 0x39000003 0x510d9439 0x351 0xd953900 0x3510d 0x96390000 0x3510d97 0x39000003 0x510d9839 0x351 0xd993900 0x3510d 0x9a390000 0x3510d9b 0x39000003 0x510d9c39 0x351 0xd9d3900 0x3510d 0x9e390000 0x3510d9f 0x39000003 0x510da039 0x351 0xda13900 0x3510d 0xa2390000 0x3510da3 0x39000003 0x510da439 0x351 0xda53900 0x3510d 0xa6390000 0x3510da7 0x39000003 0x510da839 0x351 0xda93900 0x3510d 0xaa390000 0x3510dab 0x39000003 0x510dac39 0x351 0xdad3900 0x3510d 0xae390000 0x3510daf 0x39000003 0x510db039 0x351 0xdb13900 0x3510d 0xb2390000 0x3510db3 0x39000003 0x510db439 0x351 0xdb53900 0x3510d 0xb6390000 0x3510db7 0x39000003 0x510db839 0x351 0xdb93900 0x3510d 0xba390000 0x3510dbb 0x39000003 0x510dbc39 0x351 0xdbd3900 0x3510d 0xbe390000 0x3510dbf 0x39000003 0x510dc039 0x351 0xdc13900 0x3510d 0xc2390000 0x3510dc3 0x39000003 0x510dc439 0x351 0xdc53900 0x3510d 0xc6390000 0x3510dc7 0x39000003 0x510dc839 0x351 0xdc93900 0x3510d 0xca390000 0x3510dcb 0x39000003 0x510dcc39 0x351 0xdcd3900 0x3510d 0xce390000 0x3510dcf 0x39000003 0x510dd039 0x351 0xdd13900 0x3510d 0xd2390000 0x3510dd3 0x39000003 0x510dd439 0x351 0xdd53900 0x3510d 0xd6390000 0x3510dd7 0x39000003 0x510dd839 0x351 0xdd93900 0x3510d 0xda390000 0x3510ddb 0x39000003 0x510ddc39 0x351 0xddd3900 0x3510d 0xde390000 0x3510ddf 0x39000003 0x510de039 0x351 0xde13900 0x3510d 0xe2390000 0x3510de3 0x39000003 0x510de439 0x351 0xde53900 0x3510d 0xe6390000 0x3510de7 0x39000003 0x510de839 0x351 0xde93900 0x3510d 0xea390000 0x3510deb 0x39000003 0x510dec39 0x351 0xded3900 0x3510d 0xee390000 0x3510def 0x39000003 0x510df039 0x351 0xdf13900 0x3510d 0xf2390000 0x3510df3 0x39000003 0x510df439 0x351 0xdf53900 0x3510d 0xf6390000 0x3510df7 0x39000003 0x510df839 0x351 0xdf93900 0x3510d 0xfa390000 0x3510dfb 0x39000003 0x510dfc39 0x351 0xdfd3900 0x3510d 0xfe390000 0x3510dff 0x39000003 0x510e0039 0x351 0xe013900 0x3510e 0x2390000 0x3510e03 0x39000003 0x510e0439 0x351 0xe053900 0x3510e 0x6390000 0x3510e07 0x39000003 0x510e0839 0x351 0xe093900 0x3510e 0xa390000 0x3510e0b 0x39000003 0x510e0c39 0x351 0xe0d3900 0x3510e 0xe390000 0x3510e0f 0x39000003 0x510e1039 0x351 0xe113900 0x3510e 0x12390000 0x3510e13 0x39000003 0x510e1439 0x351 0xe153900 0x3510e 0x16390000 0x3510e17 0x39000003 0x510e1839 0x351 0xe193900 0x3510e 0x1a390000 0x3510e1b 0x39000003 0x510e1c39 0x351 0xe1d3900 0x3510e 0x1e390000 0x3510e1f 0x39000003 0x510e2039 0x351 0xe213900 0x3510e 0x22390000 0x3510e23 0x39000003 0x510e2439 0x351 0xe253900 0x3510e 0x26390000 0x3510e27 0x39000003 0x510e2839 0x351 0xe293900 0x3510e 0x2a390000 0x3510e2b 0x39000003 0x510e2c39 0x351 0xe2d3900 0x3510e 0x2e390000 0x3510e2f 0x39000003 0x510e3039 0x351 0xe313900 0x3510e 0x32390000 0x3510e33 0x39000003 0x510e3439 0x351 0xe353900 0x3510e 0x36390000 0x3510e37 0x39000003 0x510e3839 0x351 0xe393900 0x3510e 0x3a390000 0x3510e3b 0x39000003 0x510e3c39 0x351 0xe3d3900 0x3510e 0x3e390000 0x3510e3f 0x39000003 0x510e4039 0x351 0xe413900 0x3510e 0x42390000 0x3510e43 0x39000003 0x510e4439 0x351 0xe453900 0x3510e 0x46390000 0x3510e47 0x39000003 0x510e4839 0x351 0xe493900 0x3510e 0x4a390000 0x3510e4b 0x39000003 0x510e4c39 0x351 0xe4d3900 0x3510e 0x4e390000 0x3510e4f 0x39000003 0x510e5039 0x351 0xe513900 0x3510e 0x52390000 0x3510e53 0x39000003 0x510e5439 0x351 0xe553900 0x3510e 0x56390000 0x3510e57 0x39000003 0x510e5839 0x351 0xe593900 0x3510e 0x5a390000 0x3510e5b 0x39000003 0x510e5c39 0x351 0xe5d3900 0x3510e 0x5e390000 0x3510e5f 0x39000003 0x510e6039 0x351 0xe613900 0x3510e 0x62390000 0x3510e63 0x39000003 0x510e6439 0x351 0xe653900 0x3510e 0x66390000 0x3510e67 0x39000003 0x510e6839 0x351 0xe693900 0x3510e 0x6a390000 0x3510e6b 0x39000003 0x510e6c39 0x351 0xe6d3900 0x3510e 0x6e390000 0x3510e6f 0x39000003 0x510e7039 0x351 0xe713900 0x3510e 0x72390000 0x3510e73 0x39000003 0x510e7439 0x351 0xe753900 0x3510e 0x76390000 0x3510e77 0x39000003 0x510e7839 0x351 0xe793900 0x3510e 0x7a390000 0x3510e7b 0x39000003 0x510e7c39 0x351 0xe7d3900 0x3510e 0x7e390000 0x3510e7f 0x39000003 0x510e8039 0x351 0xe813900 0x3510e 0x82390000 0x3510e83 0x39000003 0x510e8439 0x351 0xe853900 0x3510e 0x86390000 0x3510e87 0x39000003 0x510e8839 0x351 0xe893900 0x3510e 0x8a390000 0x3510e8b 0x39000003 0x510e8c39 0x351 0xe8d3900 0x3510e 0x8e390000 0x3510e8f 0x39000003 0x510e9039 0x351 0xe913900 0x3510e 0x92390000 0x3510e93 0x39000003 0x510e9439 0x351 0xe953900 0x3510e 0x96390000 0x3510e97 0x39000003 0x510e9839 0x351 0xe993900 0x3510e 0x9a390000 0x3510e9b 0x39000003 0x510e9c39 0x351 0xe9d3900 0x3510e 0x9e390000 0x3510e9f 0x39000003 0x510ea039 0x351 0xea13900 0x3510e 0xa2390000 0x3510ea3 0x39000003 0x510ea439 0x351 0xea53900 0x3510e 0xa6390000 0x3510ea7 0x39000003 0x510ea839 0x351 0xea93900 0x3510e 0xaa390000 0x3510eab 0x39000003 0x510eac39 0x351 0xead3900 0x3510e 0xae390000 0x3510eaf 0x39000003 0x510eb039 0x351 0xeb13900 0x3510e 0xb2390000 0x3510eb3 0x39000003 0x510eb439 0x351 0xeb53900 0x3510e 0xb6390000 0x3510eb7 0x39000003 0x510eb839 0x351 0xeb93900 0x3510e 0xba390000 0x3510ebb 0x39000003 0x510ebc39 0x351 0xebd3900 0x3510e 0xbe390000 0x3510ebf 0x39000003 0x510ec039 0x351 0xec13900 0x3510e 0xc2390000 0x3510ec3 0x39000003 0x510ec439 0x351 0xec53900 0x3510e 0xc6390000 0x3510ec7 0x39000003 0x510ec839 0x351 0xec93900 0x3510e 0xca390000 0x3510ecb 0x39000003 0x510ecc39 0x351 0xecd3900 0x3510e 0xce390000 0x3510ecf 0x39000003 0x510ed039 0x351 0xed13900 0x3510e 0xd2390000 0x3510ed3 0x39000003 0x510ed439 0x351 0xed53900 0x3510e 0xd6390000 0x3510ed7 0x39000003 0x510ed839 0x351 0xed93900 0x3510e 0xda390000 0x3510edb 0x39000003 0x510edc39 0x351 0xedd3900 0x3510e 0xde390000 0x3510edf 0x39000003 0x510ee039 0x351 0xee13900 0x3510e 0xe2390000 0x3510ee3 0x39000003 0x510ee439 0x351 0xee53900 0x3510e 0xe6390000 0x3510ee7 0x39000003 0x510ee839 0x351 0xee93900 0x3510e 0xea390000 0x3510eeb 0x39000003 0x510eec39 0x351 0xeed3900 0x3510e 0xee390000 0x3510eef 0x39000003 0x510ef039 0x351 0xef13900 0x3510e 0xf2390000 0x3510ef3 0x39000003 0x510ef439 0x351 0xef53900 0x3510e 0xf6390000 0x3510ef7 0x39000003 0x510ef839 0x351 0xef93900 0x3510e 0xfa390000 0x3510efb 0x39000003 0x510efc39 0x351 0xefd3900 0x3510e 0xfe390000 0x3510eff 0x39000003 0x510f0039 0x351 0xf013900 0x3510f 0x2390000 0x3510f03 0x39000003 0x510f0439 0x351 0xf053900 0x3510f 0x6390000 0x3510f07 0x39000003 0x510f0839 0x351 0xf093900 0x3510f 0xa390000 0x3510f0b 0x39000003 0x510f0c39 0x351 0xf0d3900 0x3510f 0xe390000 0x3510f0f 0x39000003 0x510f1039 0x351 0xf113900 0x3510f 0x12390000 0x3510f13 0x39000003 0x510f1439 0x351 0xf153900 0x3510f 0x16390000 0x3510f17 0x39000003 0x510f1839 0x351 0xf193900 0x3510f 0x1a390000 0x3510f1b 0x39000003 0x510f1c39 0x351 0xf1d3900 0x3510f 0x1e390000 0x3510f1f 0x39000003 0x510f2039 0x351 0xf213900 0x3510f 0x22390000 0x3510f23 0x39000003 0x510f2439 0x351 0xf253900 0x3510f 0x26390000 0x3510f27 0x39000003 0x510f2839 0x351 0xf293900 0x3510f 0x2a390000 0x3510f2b 0x39000003 0x510f2c39 0x351 0xf2d3900 0x3510f 0x2e390000 0x3510f2f 0x39000003 0x510f3039 0x351 0xf313900 0x3510f 0x32390000 0x3510f33 0x39000003 0x510f3439 0x351 0xf353900 0x3510f 0x36390000 0x3510f37 0x39000003 0x510f3839 0x351 0xf393900 0x3510f 0x3a390000 0x3510f3b 0x39000003 0x510f3c39 0x351 0xf3d3900 0x3510f 0x3e390000 0x3510f3f 0x39000003 0x510f4039 0x351 0xf413900 0x3510f 0x42390000 0x3510f43 0x39000003 0x510f4439 0x351 0xf453900 0x3510f 0x46390000 0x3510f47 0x39000003 0x510f4839 0x351 0xf493900 0x3510f 0x4a390000 0x3510f4b 0x39000003 0x510f4c39 0x351 0xf4d3900 0x3510f 0x4e390000 0x3510f4f 0x39000003 0x510f5039 0x351 0xf513900 0x3510f 0x52390000 0x3510f53 0x39000003 0x510f5439 0x351 0xf553900 0x3510f 0x56390000 0x3510f57 0x39000003 0x510f5839 0x351 0xf593900 0x3510f 0x5a390000 0x3510f5b 0x39000003 0x510f5c39 0x351 0xf5d3900 0x3510f 0x5e390000 0x3510f5f 0x39000003 0x510f6039 0x351 0xf613900 0x3510f 0x62390000 0x3510f63 0x39000003 0x510f6439 0x351 0xf653900 0x3510f 0x66390000 0x3510f67 0x39000003 0x510f6839 0x351 0xf693900 0x3510f 0x6a390000 0x3510f6b 0x39000003 0x510f6c39 0x351 0xf6d3900 0x3510f 0x6e390000 0x3510f6f 0x39000003 0x510f7039 0x351 0xf713900 0x3510f 0x72390000 0x3510f73 0x39000003 0x510f7439 0x351 0xf753900 0x3510f 0x76390000 0x3510f77 0x39000003 0x510f7839 0x351 0xf793900 0x3510f 0x7a390000 0x3510f7b 0x39000003 0x510f7c39 0x351 0xf7d3900 0x3510f 0x7e390000 0x3510f7f 0x39000003 0x510f8039 0x351 0xf813900 0x3510f 0x82390000 0x3510f83 0x39000003 0x510f8439 0x351 0xf853900 0x3510f 0x86390000 0x3510f87 0x39000003 0x510f8839 0x351 0xf893900 0x3510f 0x8a390000 0x3510f8b 0x39000003 0x510f8c39 0x351 0xf8d3900 0x3510f 0x8e390000 0x3510f8f 0x39000003 0x510f9039 0x351 0xf913900 0x3510f 0x92390000 0x3510f93 0x39000003 0x510f9439 0x351 0xf953900 0x3510f 0x96390000 0x3510f97 0x39000003 0x510f9839 0x351 0xf993900 0x3510f 0x9a390000 0x3510f9b 0x39000003 0x510f9c39 0x351 0xf9d3900 0x3510f 0x9e390000 0x3510f9f 0x39000003 0x510fa039 0x351 0xfa13900 0x3510f 0xa2390000 0x3510fa3 0x39000003 0x510fa439 0x351 0xfa53900 0x3510f 0xa6390000 0x3510fa7 0x39000003 0x510fa839 0x351 0xfa93900 0x3510f 0xaa390000 0x3510fab 0x39000003 0x510fac39 0x351 0xfad3900 0x3510f 0xae390000 0x3510faf 0x39000003 0x510fb039 0x351 0xfb13900 0x3510f 0xb2390000 0x3510fb3 0x39000003 0x510fb439 0x351 0xfb53900 0x3510f 0xb6390000 0x3510fb7 0x39000003 0x510fb839 0x351 0xfb93900 0x3510f 0xba390000 0x3510fbb 0x39000003 0x510fbc39 0x351 0xfbd3900 0x3510f 0xbe390000 0x3510fbf 0x39000003 0x510fc039 0x351 0xfc13900 0x3510f 0xc2390000 0x3510fc3 0x39000003 0x510fc439 0x351 0xfc53900 0x3510f 0xc6390000 0x3510fc7 0x39000003 0x510fc839 0x351 0xfc93900 0x3510f 0xca390000 0x3510fcb 0x39000003 0x510fcc39 0x351 0xfcd3900 0x3510f 0xce390000 0x3510fcf 0x39000003 0x510fd039 0x351 0xfd13900 0x3510f 0xd2390000 0x3510fd3 0x39000003 0x510fd439 0x351 0xfd53900 0x3510f 0xd6390000 0x3510fd7 0x39000003 0x510fd839 0x351 0xfd93900 0x3510f 0xda390000 0x3510fdb 0x39000003 0x510fdc39 0x351 0xfdd3900 0x3510f 0xde390000 0x3510fdf 0x39000003 0x510fe039 0x351 0xfe13900 0x3510f 0xe2390000 0x3510fe3 0x39000003 0x510fe439 0x351 0xfe53900 0x3510f 0xe6390000 0x3510fe7 0x39000003 0x510fe839 0x351 0xfe93900 0x3510f 0xea390000 0x3510feb 0x39000003 0x510fec39 0x351 0xfed3900 0x3510f 0xee390000 0x3510fef 0x39000003 0x510ff039 0x351 0xff13900 0x3510f 0xf2390000 0x3510ff3 0x39000003 0x510ff439 0x351 0xff53900 0x3510f 0xf6390000 0x3510ff7 0x39000003 0x510ff839 0x351 0xff93900 0x3510f 0xfa390000 0x3510ffb 0x39000003 0x510ffc39 0x351 0xffd3900 0x3510f 0xfe390000 0x3510fff>;
				};
			};
		};
	};
};
